[part 2 of 3: packages /E2E to /ComponentTypes]
AUTOSAR XML (schema 00048)
package /E2E
  end to end protection set E2E_ProtectionSet
    end to end protection E2E_Protection_BJB_10_XIX_BMC_CAN01: end-to-end-protection-variable-prototype=receiver=RP_IF_SG_BJB_10_XIX_BMC_HV.DE_SG_BJB_10
    end to end protection E2E_Protection_BMC_HV_10_XIX_BMC_CAN01: end-to-end-protection-variable-prototype=RT_Vishnu.Geltungsbereich_E3_1_2_Premium.SG_BMC_HV_10
    end to end protection E2E_Protection_UI1_01_XIX_BMC_CAN01: end-to-end-protection-variable-prototype=receiver=RP_IF_SG_UI1_01_XIX_BMC_HV.DE_SG_UI1_01
package /ComponentTypes
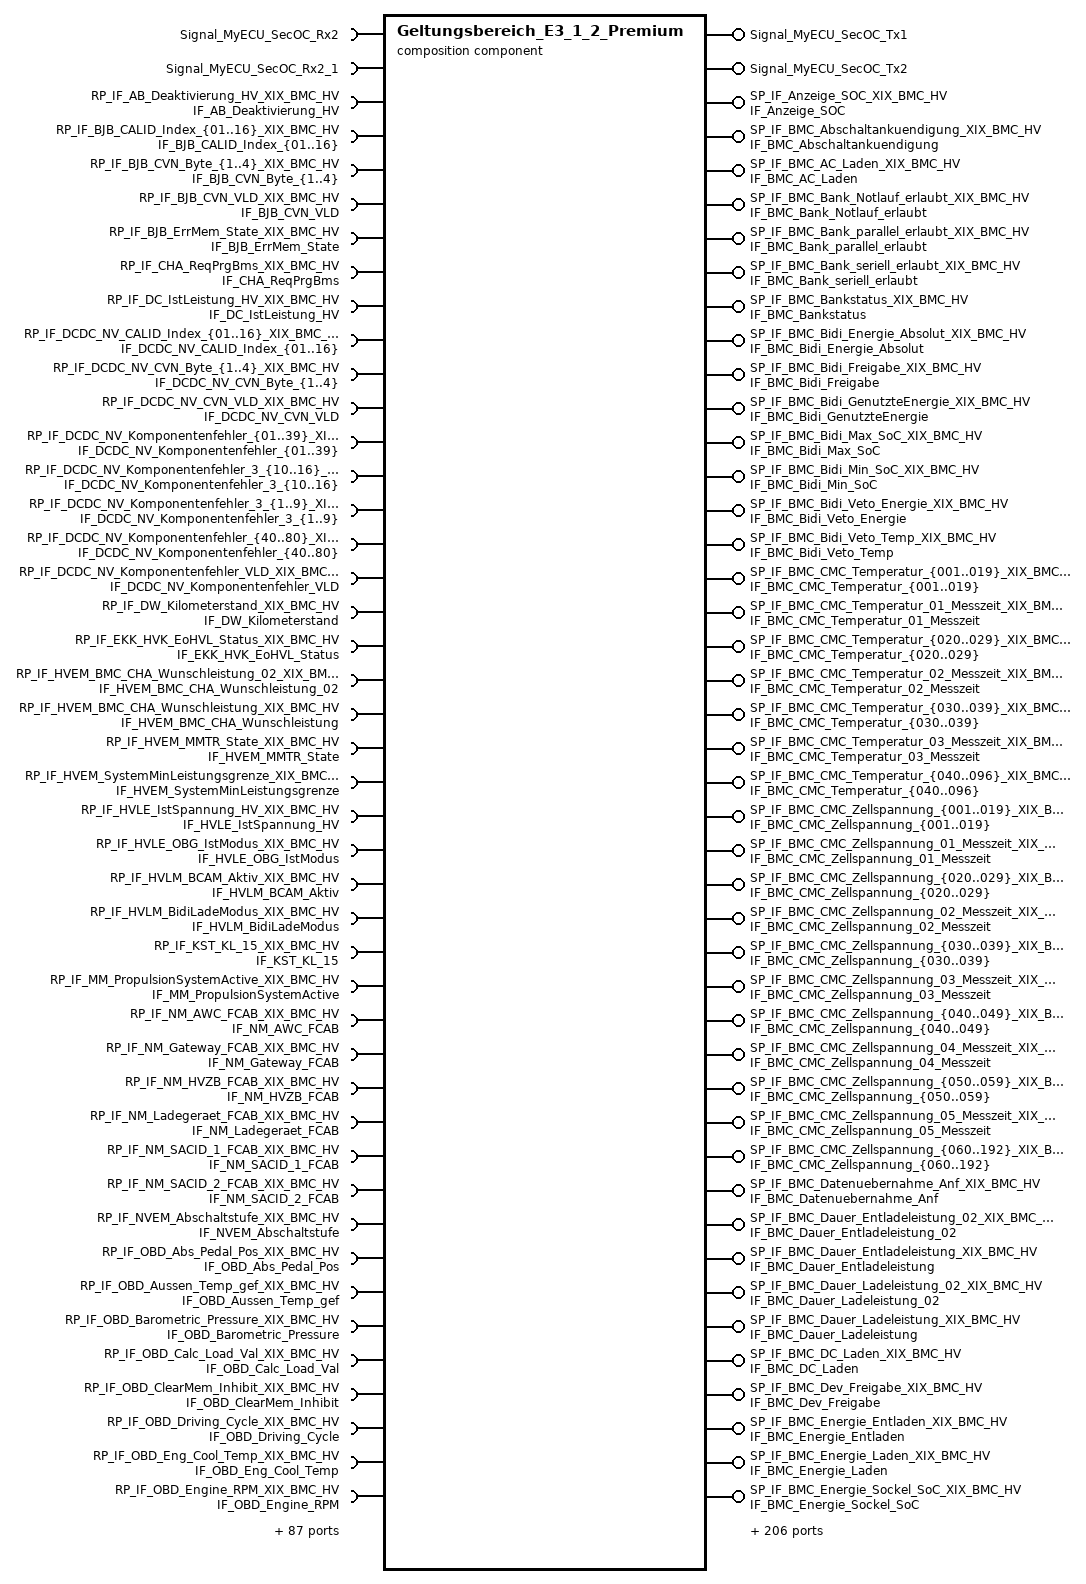
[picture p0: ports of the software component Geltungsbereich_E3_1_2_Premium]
  composition sw component type Geltungsbereich_E3_1_2_Premium
    provide port Signal_MyECU_SecOC_Tx1: nonqueued-sender-com-spec{data-element=Signal_MyECU_SecOC_Tx1, init-value=0}, provided-interface=Signal_MyECU_SecOC_Tx1
    provide port Signal_MyECU_SecOC_Tx2: nonqueued-sender-com-spec{data-element=Signal_MyECU_SecOC_Tx2, init-value=0}, provided-interface=Signal_MyECU_SecOC_Tx2
    require port Signal_MyECU_SecOC_Rx2: nonqueued-receiver-com-spec{data-element=Signal_MyECU_SecOC_Rx2, init-value=0}, required-interface=Signal_MyECU_SecOC_Rx2
    require port Signal_MyECU_SecOC_Rx2_1: nonqueued-receiver-com-spec{data-element=Signal_MyECU_SecOC_Rx2, init-value=0}, required-interface=Signal_MyECU_SecOC_Rx2_1
    519 x provide port:
      SP_IF_Anzeige_SOC_XIX_BMC_HV: nonqueued-sender-com-spec=DE_Anzeige_SOC, provided-interface=IF_Anzeige_SOC
      SP_IF_BMC_Abschaltankuendigung_XIX_BMC_HV: nonqueued-sender-com-spec=DE_BMC_Abschaltankuendigung, provided-interface=IF_BMC_Abschaltankuendigung
      SP_IF_BMC_AC_Laden_XIX_BMC_HV: nonqueued-sender-com-spec=DE_BMC_AC_Laden, provided-interface=IF_BMC_AC_Laden
      SP_IF_BMC_Bank_Notlauf_erlaubt_XIX_BMC_HV: nonqueued-sender-com-spec=DE_BMC_Bank_Notlauf_erlaubt, provided-interface=IF_BMC_Bank_Notlauf_erlaubt
      SP_IF_BMC_Bank_parallel_erlaubt_XIX_BMC_HV: nonqueued-sender-com-spec=DE_BMC_Bank_parallel_erlaubt, provided-interface=IF_BMC_Bank_parallel_erlaubt
      SP_IF_BMC_Bank_seriell_erlaubt_XIX_BMC_HV: nonqueued-sender-com-spec=DE_BMC_Bank_seriell_erlaubt, provided-interface=IF_BMC_Bank_seriell_erlaubt
      SP_IF_BMC_Bankstatus_XIX_BMC_HV: nonqueued-sender-com-spec=DE_BMC_Bankstatus, provided-interface=IF_BMC_Bankstatus
      SP_IF_BMC_Bidi_Energie_Absolut_XIX_BMC_HV: nonqueued-sender-com-spec=DE_BMC_Bidi_Energie_Absolut, provided-interface=IF_BMC_Bidi_Energie_Absolut
      SP_IF_BMC_Bidi_Freigabe_XIX_BMC_HV: nonqueued-sender-com-spec=DE_BMC_Bidi_Freigabe, provided-interface=IF_BMC_Bidi_Freigabe
      SP_IF_BMC_Bidi_GenutzteEnergie_XIX_BMC_HV: nonqueued-sender-com-spec=DE_BMC_Bidi_GenutzteEnergie, provided-interface=IF_BMC_Bidi_GenutzteEnergie
      SP_IF_BMC_Bidi_Max_SoC_XIX_BMC_HV: nonqueued-sender-com-spec=DE_BMC_Bidi_Max_SoC, provided-interface=IF_BMC_Bidi_Max_SoC
      SP_IF_BMC_Bidi_Min_SoC_XIX_BMC_HV: nonqueued-sender-com-spec=DE_BMC_Bidi_Min_SoC, provided-interface=IF_BMC_Bidi_Min_SoC
      SP_IF_BMC_Bidi_Veto_Energie_XIX_BMC_HV: nonqueued-sender-com-spec=DE_BMC_Bidi_Veto_Energie, provided-interface=IF_BMC_Bidi_Veto_Energie
      SP_IF_BMC_Bidi_Veto_Temp_XIX_BMC_HV: nonqueued-sender-com-spec=DE_BMC_Bidi_Veto_Temp, provided-interface=IF_BMC_Bidi_Veto_Temp
      SP_IF_BMC_CMC_Temperatur_{001..019}_XIX_BMC_HV: nonqueued-sender-com-spec=DE_BMC_CMC_Temperatur_{001..019}, provided-interface=IF_BMC_CMC_Temperatur_{001..019}
      SP_IF_BMC_CMC_Temperatur_01_Messzeit_XIX_BMC_HV: nonqueued-sender-com-spec=DE_BMC_CMC_Temperatur_01_Messzeit, provided-interface=IF_BMC_CMC_Temperatur_01_Messzeit
      SP_IF_BMC_CMC_Temperatur_{020..029}_XIX_BMC_HV: nonqueued-sender-com-spec=DE_BMC_CMC_Temperatur_{020..029}, provided-interface=IF_BMC_CMC_Temperatur_{020..029}
      SP_IF_BMC_CMC_Temperatur_02_Messzeit_XIX_BMC_HV: nonqueued-sender-com-spec=DE_BMC_CMC_Temperatur_02_Messzeit, provided-interface=IF_BMC_CMC_Temperatur_02_Messzeit
      SP_IF_BMC_CMC_Temperatur_{030..039}_XIX_BMC_HV: nonqueued-sender-com-spec=DE_BMC_CMC_Temperatur_{030..039}, provided-interface=IF_BMC_CMC_Temperatur_{030..039}
      SP_IF_BMC_CMC_Temperatur_03_Messzeit_XIX_BMC_HV: nonqueued-sender-com-spec=DE_BMC_CMC_Temperatur_03_Messzeit, provided-interface=IF_BMC_CMC_Temperatur_03_Messzeit
      SP_IF_BMC_CMC_Temperatur_{040..096}_XIX_BMC_HV: nonqueued-sender-com-spec=DE_BMC_CMC_Temperatur_{040..096}, provided-interface=IF_BMC_CMC_Temperatur_{040..096}
      SP_IF_BMC_CMC_Zellspannung_{001..019}_XIX_BMC_HV: nonqueued-sender-com-spec=DE_BMC_CMC_Zellspannung_{001..019}, provided-interface=IF_BMC_CMC_Zellspannung_{001..019}
      SP_IF_BMC_CMC_Zellspannung_01_Messzeit_XIX_BMC_HV: nonqueued-sender-com-spec=DE_BMC_CMC_Zellspannung_01_Messzeit, provided-interface=IF_BMC_CMC_Zellspannung_01_Messzeit
      SP_IF_BMC_CMC_Zellspannung_{020..029}_XIX_BMC_HV: nonqueued-sender-com-spec=DE_BMC_CMC_Zellspannung_{020..029}, provided-interface=IF_BMC_CMC_Zellspannung_{020..029}
      SP_IF_BMC_CMC_Zellspannung_02_Messzeit_XIX_BMC_HV: nonqueued-sender-com-spec=DE_BMC_CMC_Zellspannung_02_Messzeit, provided-interface=IF_BMC_CMC_Zellspannung_02_Messzeit
      SP_IF_BMC_CMC_Zellspannung_{030..039}_XIX_BMC_HV: nonqueued-sender-com-spec=DE_BMC_CMC_Zellspannung_{030..039}, provided-interface=IF_BMC_CMC_Zellspannung_{030..039}
      SP_IF_BMC_CMC_Zellspannung_03_Messzeit_XIX_BMC_HV: nonqueued-sender-com-spec=DE_BMC_CMC_Zellspannung_03_Messzeit, provided-interface=IF_BMC_CMC_Zellspannung_03_Messzeit
      SP_IF_BMC_CMC_Zellspannung_{040..049}_XIX_BMC_HV: nonqueued-sender-com-spec=DE_BMC_CMC_Zellspannung_{040..049}, provided-interface=IF_BMC_CMC_Zellspannung_{040..049}
      SP_IF_BMC_CMC_Zellspannung_04_Messzeit_XIX_BMC_HV: nonqueued-sender-com-spec=DE_BMC_CMC_Zellspannung_04_Messzeit, provided-interface=IF_BMC_CMC_Zellspannung_04_Messzeit
      SP_IF_BMC_CMC_Zellspannung_{050..059}_XIX_BMC_HV: nonqueued-sender-com-spec=DE_BMC_CMC_Zellspannung_{050..059}, provided-interface=IF_BMC_CMC_Zellspannung_{050..059}
      SP_IF_BMC_CMC_Zellspannung_05_Messzeit_XIX_BMC_HV: nonqueued-sender-com-spec=DE_BMC_CMC_Zellspannung_05_Messzeit, provided-interface=IF_BMC_CMC_Zellspannung_05_Messzeit
      SP_IF_BMC_CMC_Zellspannung_{060..192}_XIX_BMC_HV: nonqueued-sender-com-spec=DE_BMC_CMC_Zellspannung_{060..192}, provided-interface=IF_BMC_CMC_Zellspannung_{060..192}
      SP_IF_BMC_Datenuebernahme_Anf_XIX_BMC_HV: nonqueued-sender-com-spec=DE_BMC_Datenuebernahme_Anf, provided-interface=IF_BMC_Datenuebernahme_Anf
      SP_IF_BMC_Dauer_Entladeleistung_02_XIX_BMC_HV: nonqueued-sender-com-spec=DE_BMC_Dauer_Entladeleistung_02, provided-interface=IF_BMC_Dauer_Entladeleistung_02
      SP_IF_BMC_Dauer_Entladeleistung_XIX_BMC_HV: nonqueued-sender-com-spec=DE_BMC_Dauer_Entladeleistung, provided-interface=IF_BMC_Dauer_Entladeleistung
      SP_IF_BMC_Dauer_Ladeleistung_02_XIX_BMC_HV: nonqueued-sender-com-spec=DE_BMC_Dauer_Ladeleistung_02, provided-interface=IF_BMC_Dauer_Ladeleistung_02
      SP_IF_BMC_Dauer_Ladeleistung_XIX_BMC_HV: nonqueued-sender-com-spec=DE_BMC_Dauer_Ladeleistung, provided-interface=IF_BMC_Dauer_Ladeleistung
      SP_IF_BMC_DC_Laden_XIX_BMC_HV: nonqueued-sender-com-spec=DE_BMC_DC_Laden, provided-interface=IF_BMC_DC_Laden
      SP_IF_BMC_Dev_Freigabe_XIX_BMC_HV: nonqueued-sender-com-spec=DE_BMC_Dev_Freigabe, provided-interface=IF_BMC_Dev_Freigabe
      SP_IF_BMC_Energie_Entladen_XIX_BMC_HV: nonqueued-sender-com-spec=DE_BMC_Energie_Entladen, provided-interface=IF_BMC_Energie_Entladen
      SP_IF_BMC_Energie_Laden_XIX_BMC_HV: nonqueued-sender-com-spec=DE_BMC_Energie_Laden, provided-interface=IF_BMC_Energie_Laden
      SP_IF_BMC_Energie_Sockel_SoC_XIX_BMC_HV: nonqueued-sender-com-spec=DE_BMC_Energie_Sockel_SoC, provided-interface=IF_BMC_Energie_Sockel_SoC
      SP_IF_BMC_Energieinhalt_XIX_BMC_HV: nonqueued-sender-com-spec=DE_BMC_Energieinhalt, provided-interface=IF_BMC_Energieinhalt
      SP_IF_BMC_EnergieVorhalt_XIX_BMC_HV: nonqueued-sender-com-spec=DE_BMC_EnergieVorhalt, provided-interface=IF_BMC_EnergieVorhalt
      SP_IF_BMC_ExtLadeleistung_XIX_BMC_HV: nonqueued-sender-com-spec=DE_BMC_ExtLadeleistung, provided-interface=IF_BMC_ExtLadeleistung
      SP_IF_BMC_Fehler_Leistungsred_XIX_BMC_HV: nonqueued-sender-com-spec=DE_BMC_Fehler_Leistungsred, provided-interface=IF_BMC_Fehler_Leistungsred
      SP_IF_BMC_Fehler_Warnung_XIX_BMC_HV: nonqueued-sender-com-spec=DE_BMC_Fehler_Warnung, provided-interface=IF_BMC_Fehler_Warnung
      SP_IF_BMC_Flash_Freigabe_XIX_BMC_HV: nonqueued-sender-com-spec=DE_BMC_Flash_Freigabe, provided-interface=IF_BMC_Flash_Freigabe
      SP_IF_BMC_HV_01_BZ_XIX_BMC_HV: nonqueued-sender-com-spec=DE_BMC_HV_01_BZ, provided-interface=IF_BMC_HV_01_BZ
      SP_IF_BMC_HV_01_CRC_XIX_BMC_HV: nonqueued-sender-com-spec=DE_BMC_HV_01_CRC, provided-interface=IF_BMC_HV_01_CRC
      SP_IF_BMC_HV_02_BZ_XIX_BMC_HV: nonqueued-sender-com-spec=DE_BMC_HV_02_BZ, provided-interface=IF_BMC_HV_02_BZ
      SP_IF_BMC_HV_02_CRC_XIX_BMC_HV: nonqueued-sender-com-spec=DE_BMC_HV_02_CRC, provided-interface=IF_BMC_HV_02_CRC
      SP_IF_BMC_HV_04_BZ_XIX_BMC_HV: nonqueued-sender-com-spec=DE_BMC_HV_04_BZ, provided-interface=IF_BMC_HV_04_BZ
      SP_IF_BMC_HV_04_CRC_XIX_BMC_HV: nonqueued-sender-com-spec=DE_BMC_HV_04_CRC, provided-interface=IF_BMC_HV_04_CRC
      SP_IF_BMC_HV_10_BZ_XIX_BMC_HV: nonqueued-sender-com-spec=DE_BMC_HV_10_BZ, provided-interface=IF_BMC_HV_10_BZ
      SP_IF_BMC_HV_10_CRC_XIX_BMC_HV: nonqueued-sender-com-spec=DE_BMC_HV_10_CRC, provided-interface=IF_BMC_HV_10_CRC
      SP_IF_BMC_HV_11_BZ_XIX_BMC_HV: nonqueued-sender-com-spec=DE_BMC_HV_11_BZ, provided-interface=IF_BMC_HV_11_BZ
      SP_IF_BMC_HV_11_CRC_XIX_BMC_HV: nonqueued-sender-com-spec=DE_BMC_HV_11_CRC, provided-interface=IF_BMC_HV_11_CRC
      SP_IF_BMC_HV_12_BZ_XIX_BMC_HV: nonqueued-sender-com-spec=DE_BMC_HV_12_BZ, provided-interface=IF_BMC_HV_12_BZ
      SP_IF_BMC_HV_12_CRC_XIX_BMC_HV: nonqueued-sender-com-spec=DE_BMC_HV_12_CRC, provided-interface=IF_BMC_HV_12_CRC
      SP_IF_BMC_HV_13_BZ_XIX_BMC_HV: nonqueued-sender-com-spec=DE_BMC_HV_13_BZ, provided-interface=IF_BMC_HV_13_BZ
      SP_IF_BMC_HV_13_CRC_XIX_BMC_HV: nonqueued-sender-com-spec=DE_BMC_HV_13_CRC, provided-interface=IF_BMC_HV_13_CRC
      SP_IF_BMC_HVK_EoHVL_Status_XIX_BMC_HV: nonqueued-sender-com-spec=DE_BMC_HVK_EoHVL_Status, provided-interface=IF_BMC_HVK_EoHVL_Status
      SP_IF_BMC_HVK_Fehler_HVIL_XIX_BMC_HV: nonqueued-sender-com-spec=DE_BMC_HVK_Fehler_HVIL, provided-interface=IF_BMC_HVK_Fehler_HVIL
      SP_IF_BMC_HVK_Fehler_Intern_XIX_BMC_HV: nonqueued-sender-com-spec=DE_BMC_HVK_Fehler_Intern, provided-interface=IF_BMC_HVK_Fehler_Intern
      SP_IF_BMC_HVK_Fehler_SD_XIX_BMC_HV: nonqueued-sender-com-spec=DE_BMC_HVK_Fehler_SD, provided-interface=IF_BMC_HVK_Fehler_SD
      SP_IF_BMC_Iso_Mode_Anf_XIX_BMC_HV: nonqueued-sender-com-spec=DE_BMC_Iso_Mode_Anf, provided-interface=IF_BMC_Iso_Mode_Anf
      SP_IF_BMC_IstTemperaturMax_Modul_ID_XIX_BMC_HV: nonqueued-sender-com-spec=DE_BMC_IstTemperaturMax_Modul_ID, provided-interface=IF_BMC_IstTemperaturMax_Modul_ID
      SP_IF_BMC_IstTemperaturMax_Sensor_ID_XIX_BMC_HV: nonqueued-sender-com-spec=DE_BMC_IstTemperaturMax_Sensor_ID, provided-interface=IF_BMC_IstTemperaturMax_Sensor_ID
      SP_IF_BMC_IstTemperaturMin_Modul_ID_XIX_BMC_HV: nonqueued-sender-com-spec=DE_BMC_IstTemperaturMin_Modul_ID, provided-interface=IF_BMC_IstTemperaturMin_Modul_ID
      SP_IF_BMC_IstTemperaturMin_Sensor_ID_XIX_BMC_HV: nonqueued-sender-com-spec=DE_BMC_IstTemperaturMin_Sensor_ID, provided-interface=IF_BMC_IstTemperaturMin_Sensor_ID
      SP_IF_BMC_IstZellSpannungMax_Modul_ID_XIX_BMC_HV: nonqueued-sender-com-spec=DE_BMC_IstZellSpannungMax_Modul_ID, provided-interface=IF_BMC_IstZellSpannungMax_Modul_ID
      SP_IF_BMC_IstZellspannungMax_XIX_BMC_HV: nonqueued-sender-com-spec=DE_BMC_IstZellspannungMax, provided-interface=IF_BMC_IstZellspannungMax
      SP_IF_BMC_IstZellSpannungMax_Zell_ID_XIX_BMC_HV: nonqueued-sender-com-spec=DE_BMC_IstZellSpannungMax_Zell_ID, provided-interface=IF_BMC_IstZellSpannungMax_Zell_ID
      SP_IF_BMC_IstZellSpannungMin_Modul_ID_XIX_BMC_HV: nonqueued-sender-com-spec=DE_BMC_IstZellSpannungMin_Modul_ID, provided-interface=IF_BMC_IstZellSpannungMin_Modul_ID
      SP_IF_BMC_IstZellspannungMin_XIX_BMC_HV: nonqueued-sender-com-spec=DE_BMC_IstZellspannungMin, provided-interface=IF_BMC_IstZellspannungMin
      SP_IF_BMC_IstZellSpannungMin_Zell_ID_XIX_BMC_HV: nonqueued-sender-com-spec=DE_BMC_IstZellSpannungMin_Zell_ID, provided-interface=IF_BMC_IstZellSpannungMin_Zell_ID
      SP_IF_BMC_IWU_Status_XIX_BMC_HV: nonqueued-sender-com-spec=DE_BMC_IWU_Status, provided-interface=IF_BMC_IWU_Status
      SP_IF_BMC_IWU_Wert_neg_XIX_BMC_HV: nonqueued-sender-com-spec=DE_BMC_IWU_Wert_neg, provided-interface=IF_BMC_IWU_Wert_neg
      SP_IF_BMC_IWU_Wert_pos_XIX_BMC_HV: nonqueued-sender-com-spec=DE_BMC_IWU_Wert_pos, provided-interface=IF_BMC_IWU_Wert_pos
      SP_IF_BMC_Konditionierung_Anf_XIX_BMC_HV: nonqueued-sender-com-spec=DE_BMC_Konditionierung_Anf, provided-interface=IF_BMC_Konditionierung_Anf
      SP_IF_BMC_KundenWarnung_XIX_BMC_HV: nonqueued-sender-com-spec=DE_BMC_KundenWarnung, provided-interface=IF_BMC_KundenWarnung
      SP_IF_BMC_Lebensdauer_Trennelemente_XIX_BMC_HV: nonqueued-sender-com-spec=DE_BMC_Lebensdauer_Trennelemente, provided-interface=IF_BMC_Lebensdauer_Trennelemente
      SP_IF_BMC_Leerlaufspannung_XIX_BMC_HV: nonqueued-sender-com-spec=DE_BMC_Leerlaufspannung, provided-interface=IF_BMC_Leerlaufspannung
      SP_IF_BMC_Max_Entladeleistung_02_XIX_BMC_HV: nonqueued-sender-com-spec=DE_BMC_Max_Entladeleistung_02, provided-interface=IF_BMC_Max_Entladeleistung_02
      SP_IF_BMC_Max_Entladeleistung_XIX_BMC_HV: nonqueued-sender-com-spec=DE_BMC_Max_Entladeleistung, provided-interface=IF_BMC_Max_Entladeleistung
      SP_IF_BMC_Max_Entladestrom_02_XIX_BMC_HV: nonqueued-sender-com-spec=DE_BMC_Max_Entladestrom_02, provided-interface=IF_BMC_Max_Entladestrom_02
      SP_IF_BMC_Max_Entladestrom_XIX_BMC_HV: nonqueued-sender-com-spec=DE_BMC_Max_Entladestrom, provided-interface=IF_BMC_Max_Entladestrom
      SP_IF_BMC_Max_Ladeleistung_02_XIX_BMC_HV: nonqueued-sender-com-spec=DE_BMC_Max_Ladeleistung_02, provided-interface=IF_BMC_Max_Ladeleistung_02
      SP_IF_BMC_Max_Ladeleistung_XIX_BMC_HV: nonqueued-sender-com-spec=DE_BMC_Max_Ladeleistung, provided-interface=IF_BMC_Max_Ladeleistung
      SP_IF_BMC_Max_Ladestrom_02_XIX_BMC_HV: nonqueued-sender-com-spec=DE_BMC_Max_Ladestrom_02, provided-interface=IF_BMC_Max_Ladestrom_02
      SP_IF_BMC_Max_Ladestrom_XIX_BMC_HV: nonqueued-sender-com-spec=DE_BMC_Max_Ladestrom, provided-interface=IF_BMC_Max_Ladestrom
      SP_IF_BMC_Max_Spannung_XIX_BMC_HV: nonqueued-sender-com-spec=DE_BMC_Max_Spannung, provided-interface=IF_BMC_Max_Spannung
      SP_IF_BMC_MaxEnergieinhalt_XIX_BMC_HV: nonqueued-sender-com-spec=DE_BMC_MaxEnergieinhalt, provided-interface=IF_BMC_MaxEnergieinhalt
      SP_IF_BMC_Min_Spannung_XIX_BMC_HV: nonqueued-sender-com-spec=DE_BMC_Min_Spannung, provided-interface=IF_BMC_Min_Spannung
      SP_IF_BMC_MinDyn_Entladespannung_XIX_BMC_HV: nonqueued-sender-com-spec=DE_BMC_MinDyn_Entladespannung, provided-interface=IF_BMC_MinDyn_Entladespannung
      SP_IF_BMC_MinDyn_Ladespannung_XIX_BMC_HV: nonqueued-sender-com-spec=DE_BMC_MinDyn_Ladespannung, provided-interface=IF_BMC_MinDyn_Ladespannung
      SP_IF_BMC_MMTR_Status_XIX_BMC_HV: nonqueued-sender-com-spec=DE_BMC_MMTR_Status, provided-interface=IF_BMC_MMTR_Status
      SP_IF_BMC_Modus_XIX_BMC_HV: nonqueued-sender-com-spec=DE_BMC_Modus, provided-interface=IF_BMC_Modus
      SP_IF_BMC_NutzbareKapazitaet_XIX_BMC_HV: nonqueued-sender-com-spec=DE_BMC_NutzbareKapazitaet, provided-interface=IF_BMC_NutzbareKapazitaet
      SP_IF_BMC_NutzbarerSOC_XIX_BMC_HV: nonqueued-sender-com-spec=DE_BMC_NutzbarerSOC, provided-interface=IF_BMC_NutzbarerSOC
      SP_IF_BMC_Pack_SN_{01..26}_XIX_BMC_HV: nonqueued-sender-com-spec=DE_BMC_Pack_SN_{01..26}, provided-interface=IF_BMC_Pack_SN_{01..26}
      SP_IF_BMC_PCM_VTD_Freeze_Req_XIX_BMC_HV: nonqueued-sender-com-spec=DE_BMC_PCM_VTD_Freeze_Req, provided-interface=IF_BMC_PCM_VTD_Freeze_Req
      SP_IF_BMC_PCM_VTD_LifeTimeReset_Req_XIX_BMC_HV: nonqueued-sender-com-spec=DE_BMC_PCM_VTD_LifeTimeReset_Req, provided-interface=IF_BMC_PCM_VTD_LifeTimeReset_Req
      SP_IF_BMC_PCM_VTD_LifeTimeReset_Resp_XIX_BMC_HV: nonqueued-sender-com-spec=DE_BMC_PCM_VTD_LifeTimeReset_Resp, provided-interface=IF_BMC_PCM_VTD_LifeTimeReset_Resp
      SP_IF_BMC_PCM_VTD_RecentReset_Req_XIX_BMC_HV: nonqueued-sender-com-spec=DE_BMC_PCM_VTD_RecentReset_Req, provided-interface=IF_BMC_PCM_VTD_RecentReset_Req
      SP_IF_BMC_PerfInd_Entladen_XIX_BMC_HV: nonqueued-sender-com-spec=DE_BMC_PerfInd_Entladen, provided-interface=IF_BMC_PerfInd_Entladen
      SP_IF_BMC_PerfInd_Laden_XIX_BMC_HV: nonqueued-sender-com-spec=DE_BMC_PerfInd_Laden, provided-interface=IF_BMC_PerfInd_Laden
      SP_IF_BMC_PredLeistung_StuetzungNV_XIX_BMC_HV: nonqueued-sender-com-spec=DE_BMC_PredLeistung_StuetzungNV, provided-interface=IF_BMC_PredLeistung_StuetzungNV
      SP_IF_BMC_Range_Indikator_XIX_BMC_HV: nonqueued-sender-com-spec=DE_BMC_Range_Indikator, provided-interface=IF_BMC_Range_Indikator
      SP_IF_BMC_Rekuperation_Ueberlauf_XIX_BMC_HV: nonqueued-sender-com-spec=DE_BMC_Rekuperation_Ueberlauf, provided-interface=IF_BMC_Rekuperation_Ueberlauf
      SP_IF_BMC_Rekuperation_XIX_BMC_HV: nonqueued-sender-com-spec=DE_BMC_Rekuperation, provided-interface=IF_BMC_Rekuperation
      SP_IF_BMC_RtmWarnBattUnautorisiert_XIX_BMC_HV: nonqueued-sender-com-spec=DE_BMC_RtmWarnBattUnautorisiert, provided-interface=IF_BMC_RtmWarnBattUnautorisiert
      SP_IF_BMC_RtmWarnPackKommunikation_XIX_BMC_HV: nonqueued-sender-com-spec=DE_BMC_RtmWarnPackKommunikation, provided-interface=IF_BMC_RtmWarnPackKommunikation
      SP_IF_BMC_RtmWarnPackUeberladen_XIX_BMC_HV: nonqueued-sender-com-spec=DE_BMC_RtmWarnPackUeberladen, provided-interface=IF_BMC_RtmWarnPackUeberladen
      SP_IF_BMC_RtmWarnSocHoch_XIX_BMC_HV: nonqueued-sender-com-spec=DE_BMC_RtmWarnSocHoch, provided-interface=IF_BMC_RtmWarnSocHoch
      SP_IF_BMC_RtmWarnSocNiedrig_XIX_BMC_HV: nonqueued-sender-com-spec=DE_BMC_RtmWarnSocNiedrig, provided-interface=IF_BMC_RtmWarnSocNiedrig
      SP_IF_BMC_RtmWarnSocSprung_XIX_BMC_HV: nonqueued-sender-com-spec=DE_BMC_RtmWarnSocSprung, provided-interface=IF_BMC_RtmWarnSocSprung
      SP_IF_BMC_RtmWarnTZelleDiff_XIX_BMC_HV: nonqueued-sender-com-spec=DE_BMC_RtmWarnTZelleDiff, provided-interface=IF_BMC_RtmWarnTZelleDiff
      SP_IF_BMC_RtmWarnTZelleMax_XIX_BMC_HV: nonqueued-sender-com-spec=DE_BMC_RtmWarnTZelleMax, provided-interface=IF_BMC_RtmWarnTZelleMax
      SP_IF_BMC_RtmWarnTZelleMin_XIX_BMC_HV: nonqueued-sender-com-spec=DE_BMC_RtmWarnTZelleMin, provided-interface=IF_BMC_RtmWarnTZelleMin
      SP_IF_BMC_RtmWarnUeberstrom_XIX_BMC_HV: nonqueued-sender-com-spec=DE_BMC_RtmWarnUeberstrom, provided-interface=IF_BMC_RtmWarnUeberstrom
      SP_IF_BMC_RtmWarnUPackMax_XIX_BMC_HV: nonqueued-sender-com-spec=DE_BMC_RtmWarnUPackMax, provided-interface=IF_BMC_RtmWarnUPackMax
      SP_IF_BMC_RtmWarnUPackMin_XIX_BMC_HV: nonqueued-sender-com-spec=DE_BMC_RtmWarnUPackMin, provided-interface=IF_BMC_RtmWarnUPackMin
      SP_IF_BMC_RtmWarnUZelleMax_XIX_BMC_HV: nonqueued-sender-com-spec=DE_BMC_RtmWarnUZelleMax, provided-interface=IF_BMC_RtmWarnUZelleMax
      SP_IF_BMC_RtmWarnUZelleMin_XIX_BMC_HV: nonqueued-sender-com-spec=DE_BMC_RtmWarnUZelleMin, provided-interface=IF_BMC_RtmWarnUZelleMin
      SP_IF_BMC_RtmWarnZelleZustand_XIX_BMC_HV: nonqueued-sender-com-spec=DE_BMC_RtmWarnZelleZustand, provided-interface=IF_BMC_RtmWarnZelleZustand
      SP_IF_BMC_RuecklaufTemperatur_XIX_BMC_HV: nonqueued-sender-com-spec=DE_BMC_RuecklaufTemperatur, provided-interface=IF_BMC_RuecklaufTemperatur
      SP_IF_BMC_Spannung_DC_Ladesaeule_XIX_BMC_HV: nonqueued-sender-com-spec=DE_BMC_Spannung_DC_Ladesaeule, provided-interface=IF_BMC_Spannung_DC_Ladesaeule
      SP_IF_BMC_Spannung_Messzeit_XIX_BMC_HV: nonqueued-sender-com-spec=DE_BMC_Spannung_Messzeit, provided-interface=IF_BMC_Spannung_Messzeit
      SP_IF_BMC_Spannung_XIX_BMC_HV: nonqueued-sender-com-spec=DE_BMC_Spannung, provided-interface=IF_BMC_Spannung
      SP_IF_BMC_Spannung_ZwischenKreis_2_XIX_BMC_HV: nonqueued-sender-com-spec=DE_BMC_Spannung_ZwischenKreis_2, provided-interface=IF_BMC_Spannung_ZwischenKreis_2
      SP_IF_BMC_Spannung_ZwischenKreis_XIX_BMC_HV: nonqueued-sender-com-spec=DE_BMC_Spannung_ZwischenKreis, provided-interface=IF_BMC_Spannung_ZwischenKreis
      SP_IF_BMC_Sperrung_Ueberspannung_XIX_BMC_HV: nonqueued-sender-com-spec=DE_BMC_Sperrung_Ueberspannung, provided-interface=IF_BMC_Sperrung_Ueberspannung
      SP_IF_BMC_Sperrung_Uebertemperatur_XIX_BMC_HV: nonqueued-sender-com-spec=DE_BMC_Sperrung_Uebertemperatur, provided-interface=IF_BMC_Sperrung_Uebertemperatur
      SP_IF_BMC_Sperrung_Unterspannung_XIX_BMC_HV: nonqueued-sender-com-spec=DE_BMC_Sperrung_Unterspannung, provided-interface=IF_BMC_Sperrung_Unterspannung
      SP_IF_BMC_Status_DCLS_XIX_BMC_HV: nonqueued-sender-com-spec=DE_BMC_Status_DCLS, provided-interface=IF_BMC_Status_DCLS
      SP_IF_BMC_Status_HV_Spannungssensorik_XIX_BMC_HV: nonqueued-sender-com-spec=DE_BMC_Status_HV_Spannungssensorik, provided-interface=IF_BMC_Status_HV_Spannungssensorik
      SP_IF_BMC_Status_Spgfreiheit_XIX_BMC_HV: nonqueued-sender-com-spec=DE_BMC_Status_Spgfreiheit, provided-interface=IF_BMC_Status_Spgfreiheit
      SP_IF_BMC_Status_Trennelemente_XIX_BMC_HV: nonqueued-sender-com-spec=DE_BMC_Status_Trennelemente, provided-interface=IF_BMC_Status_Trennelemente
      SP_IF_BMC_Strom_02_XIX_BMC_HV: nonqueued-sender-com-spec=DE_BMC_Strom_02, provided-interface=IF_BMC_Strom_02
      SP_IF_BMC_Strom_Messzeit_XIX_BMC_HV: nonqueued-sender-com-spec=DE_BMC_Strom_Messzeit, provided-interface=IF_BMC_Strom_Messzeit
      SP_IF_BMC_Strom_XIX_BMC_HV: nonqueued-sender-com-spec=DE_BMC_Strom, provided-interface=IF_BMC_Strom
      SP_IF_BMC_TechnischerSOC_XIX_BMC_HV: nonqueued-sender-com-spec=DE_BMC_TechnischerSOC, provided-interface=IF_BMC_TechnischerSOC
      SP_IF_BMC_Temperatur_hoechste_XIX_BMC_HV: nonqueued-sender-com-spec=DE_BMC_Temperatur_hoechste, provided-interface=IF_BMC_Temperatur_hoechste
      SP_IF_BMC_Temperatur_niedrigste_XIX_BMC_HV: nonqueued-sender-com-spec=DE_BMC_Temperatur_niedrigste, provided-interface=IF_BMC_Temperatur_niedrigste
      SP_IF_BMC_Temperatur_XIX_BMC_HV: nonqueued-sender-com-spec=DE_BMC_Temperatur, provided-interface=IF_BMC_Temperatur
      SP_IF_BMC_ThermAuslastung_XIX_BMC_HV: nonqueued-sender-com-spec=DE_BMC_ThermAuslastung, provided-interface=IF_BMC_ThermAuslastung
      SP_IF_BMC_ThermSpreizung_XIX_BMC_HV: nonqueued-sender-com-spec=DE_BMC_ThermSpreizung, provided-interface=IF_BMC_ThermSpreizung
      SP_IF_BMC_UBE_Indik_last_update_km_XIX_BMC_HV: nonqueued-sender-com-spec=DE_BMC_UBE_Indik_last_update_km, provided-interface=IF_BMC_UBE_Indik_last_update_km
      SP_IF_BMC_UBE_Indikator_XIX_BMC_HV: nonqueued-sender-com-spec=DE_BMC_UBE_Indikator, provided-interface=IF_BMC_UBE_Indikator
      SP_IF_BMC_Ueberspannungszaehler_CMC{01..04}_XIX_BMC_HV: nonqueued-sender-com-spec=DE_BMC_Ueberspannungszaehler_CMC{01..04}, provided-interface=IF_BMC_Ueberspannungszaehler_CMC{01..04}
      SP_IF_BMC_Uebertemperaturzaehler_CMC{01..04}_XIX_BMC_HV: nonqueued-sender-com-spec=DE_BMC_Uebertemperaturzaehler_CMC{01..04}, provided-interface=IF_BMC_Uebertemperaturzaehler_CMC{01..04}
      SP_IF_BMC_UI1_Spannung1_Schalt_Anf_XIX_BMC_HV: nonqueued-sender-com-spec=DE_BMC_UI1_Spannung1_Schalt_Anf, provided-interface=IF_BMC_UI1_Spannung1_Schalt_Anf
      SP_IF_BMC_UI1_Spannung2_Schalt_Anf_XIX_BMC_HV: nonqueued-sender-com-spec=DE_BMC_UI1_Spannung2_Schalt_Anf, provided-interface=IF_BMC_UI1_Spannung2_Schalt_Anf
      SP_IF_BMC_UI2_Spannung1_Schalt_Anf_XIX_BMC_HV: nonqueued-sender-com-spec=DE_BMC_UI2_Spannung1_Schalt_Anf, provided-interface=IF_BMC_UI2_Spannung1_Schalt_Anf
      SP_IF_BMC_UI2_Spannung2_Schalt_Anf_XIX_BMC_HV: nonqueued-sender-com-spec=DE_BMC_UI2_Spannung2_Schalt_Anf, provided-interface=IF_BMC_UI2_Spannung2_Schalt_Anf
      SP_IF_BMC_Unterboden_Warnung_XIX_BMC_HV: nonqueued-sender-com-spec=DE_BMC_Unterboden_Warnung, provided-interface=IF_BMC_Unterboden_Warnung
      SP_IF_BMC_Unterspannungszaehler_CMC{01..04}_XIX_BMC_HV: nonqueued-sender-com-spec=DE_BMC_Unterspannungszaehler_CMC{01..04}, provided-interface=IF_BMC_Unterspannungszaehler_CMC{01..04}
      SP_IF_BMC_Verbauinfo_ACSchuetz_XIX_BMC_HV: nonqueued-sender-com-spec=DE_BMC_Verbauinfo_ACSchuetz, provided-interface=IF_BMC_Verbauinfo_ACSchuetz
      SP_IF_BMC_Verbauinfo_Bank_XIX_BMC_HV: nonqueued-sender-com-spec=DE_BMC_Verbauinfo_Bank, provided-interface=IF_BMC_Verbauinfo_Bank
      SP_IF_BMC_Verbrauch_Ueberlauf_XIX_BMC_HV: nonqueued-sender-com-spec=DE_BMC_Verbrauch_Ueberlauf, provided-interface=IF_BMC_Verbrauch_Ueberlauf
      SP_IF_BMC_Verbrauch_XIX_BMC_HV: nonqueued-sender-com-spec=DE_BMC_Verbrauch, provided-interface=IF_BMC_Verbrauch
      SP_IF_BMC_VerlustEnergie_XIX_BMC_HV: nonqueued-sender-com-spec=DE_BMC_VerlustEnergie, provided-interface=IF_BMC_VerlustEnergie
      SP_IF_BMC_Vorlade_Zielspannung_XIX_BMC_HV: nonqueued-sender-com-spec=DE_BMC_Vorlade_Zielspannung, provided-interface=IF_BMC_Vorlade_Zielspannung
      SP_IF_BMC_VorlaufTemperatur_XIX_BMC_HV: nonqueued-sender-com-spec=DE_BMC_VorlaufTemperatur, provided-interface=IF_BMC_VorlaufTemperatur
      SP_IF_BMC_ZellTemp_virtuell_max_XIX_BMC_HV: nonqueued-sender-com-spec=DE_BMC_ZellTemp_virtuell_max, provided-interface=IF_BMC_ZellTemp_virtuell_max
      SP_IF_BMC_ZellTemp_virtuell_min_XIX_BMC_HV: nonqueued-sender-com-spec=DE_BMC_ZellTemp_virtuell_min, provided-interface=IF_BMC_ZellTemp_virtuell_min
      SP_IF_DS_Hybrid_01_ConfDTCChanged_XIX_BMC_HV: nonqueued-sender-com-spec=DE_DS_Hybrid_01_ConfDTCChanged, provided-interface=IF_DS_Hybrid_01_ConfDTCChanged
      SP_IF_DS_Hybrid_01_DiagAdr_XIX_BMC_HV: nonqueued-sender-com-spec=DE_DS_Hybrid_01_DiagAdr, provided-interface=IF_DS_Hybrid_01_DiagAdr
      SP_IF_DS_Hybrid_01_IdentValid_XIX_BMC_HV: nonqueued-sender-com-spec=DE_DS_Hybrid_01_IdentValid, provided-interface=IF_DS_Hybrid_01_IdentValid
      SP_IF_DS_Hybrid_01_Lokalaktiv_XIX_BMC_HV: nonqueued-sender-com-spec=DE_DS_Hybrid_01_Lokalaktiv, provided-interface=IF_DS_Hybrid_01_Lokalaktiv
      SP_IF_DS_Hybrid_01_MemSel10Changed_XIX_BMC_HV: nonqueued-sender-com-spec=DE_DS_Hybrid_01_MemSel10Changed, provided-interface=IF_DS_Hybrid_01_MemSel10Changed
      SP_IF_DS_Hybrid_01_MemSelChanged_XIX_BMC_HV: nonqueued-sender-com-spec=DE_DS_Hybrid_01_MemSelChanged, provided-interface=IF_DS_Hybrid_01_MemSelChanged
      SP_IF_DS_Hybrid_01_StMemChanged_XIX_BMC_HV: nonqueued-sender-com-spec=DE_DS_Hybrid_01_StMemChanged, provided-interface=IF_DS_Hybrid_01_StMemChanged
      SP_IF_DS_Hybrid_01_Subsystemaktiv_XIX_BMC_HV: nonqueued-sender-com-spec=DE_DS_Hybrid_01_Subsystemaktiv, provided-interface=IF_DS_Hybrid_01_Subsystemaktiv
      SP_IF_DS_Hybrid_01_TestFailedChanged_XIX_BMC_HV: nonqueued-sender-com-spec=DE_DS_Hybrid_01_TestFailedChanged, provided-interface=IF_DS_Hybrid_01_TestFailedChanged
      SP_IF_DS_Hybrid_01_WIRChanged_XIX_BMC_HV: nonqueued-sender-com-spec=DE_DS_Hybrid_01_WIRChanged, provided-interface=IF_DS_Hybrid_01_WIRChanged
      SP_IF_Hybrid_01_Indc_StChk_XIX_BMC_HV: nonqueued-sender-com-spec=DE_Hybrid_01_Indc_StChk, provided-interface=IF_Hybrid_01_Indc_StChk
      SP_IF_Hybrid_01_Indc_StFail_XIX_BMC_HV: nonqueued-sender-com-spec=DE_Hybrid_01_Indc_StFail, provided-interface=IF_Hybrid_01_Indc_StFail
      SP_IF_Hybrid_01_KD_Fehler_XIX_BMC_HV: nonqueued-sender-com-spec=DE_Hybrid_01_KD_Fehler, provided-interface=IF_Hybrid_01_KD_Fehler
      SP_IF_Hybrid_01_Nachlauftyp_XIX_BMC_HV: nonqueued-sender-com-spec=DE_Hybrid_01_Nachlauftyp, provided-interface=IF_Hybrid_01_Nachlauftyp
      SP_IF_Hybrid_01_OBD_Lampe_Anf_XIX_BMC_HV: nonqueued-sender-com-spec=DE_Hybrid_01_OBD_Lampe_Anf, provided-interface=IF_Hybrid_01_OBD_Lampe_Anf
      SP_IF_Hybrid_01_SNI_10_XIX_BMC_HV: nonqueued-sender-com-spec=DE_Hybrid_01_SNI_10, provided-interface=IF_Hybrid_01_SNI_10
      SP_IF_KN_Hybrid_01_DiagPfad_V12_XIX_BMC_HV: nonqueued-sender-com-spec=DE_KN_Hybrid_01_DiagPfad_V12, provided-interface=IF_KN_Hybrid_01_DiagPfad_V12
      SP_IF_KS_Hybrid_01_ChK_IKACtr_XIX_BMC_HV: nonqueued-sender-com-spec=DE_KS_Hybrid_01_ChK_IKACtr, provided-interface=IF_KS_Hybrid_01_ChK_IKACtr
      SP_IF_KS_Hybrid_01_ChK_SID_XIX_BMC_HV: nonqueued-sender-com-spec=DE_KS_Hybrid_01_ChK_SID, provided-interface=IF_KS_Hybrid_01_ChK_SID
      SP_IF_KS_Hybrid_01_ChK_XIX_BMC_HV: nonqueued-sender-com-spec=DE_KS_Hybrid_01_ChK, provided-interface=IF_KS_Hybrid_01_ChK
      SP_IF_KS_Hybrid_01_ReK_IKACtr_XIX_BMC_HV: nonqueued-sender-com-spec=DE_KS_Hybrid_01_ReK_IKACtr, provided-interface=IF_KS_Hybrid_01_ReK_IKACtr
      SP_IF_KS_Hybrid_01_ReK_SID_XIX_BMC_HV: nonqueued-sender-com-spec=DE_KS_Hybrid_01_ReK_SID, provided-interface=IF_KS_Hybrid_01_ReK_SID
      SP_IF_KS_Hybrid_01_ReK_XIX_BMC_HV: nonqueued-sender-com-spec=DE_KS_Hybrid_01_ReK, provided-interface=IF_KS_Hybrid_01_ReK
      SP_IF_KS_Hybrid_01_Req_ErrCtr_XIX_BMC_HV: nonqueued-sender-com-spec=DE_KS_Hybrid_01_Req_ErrCtr, provided-interface=IF_KS_Hybrid_01_Req_ErrCtr
      SP_IF_KS_Hybrid_01_Req_IKA_Retry_XIX_BMC_HV: nonqueued-sender-com-spec=DE_KS_Hybrid_01_Req_IKA_Retry, provided-interface=IF_KS_Hybrid_01_Req_IKA_Retry
      SP_IF_KS_Hybrid_01_Req_Prio_XIX_BMC_HV: nonqueued-sender-com-spec=DE_KS_Hybrid_01_Req_Prio, provided-interface=IF_KS_Hybrid_01_Req_Prio
      SP_IF_KS_Hybrid_01_Req_SID_XIX_BMC_HV: nonqueued-sender-com-spec=DE_KS_Hybrid_01_Req_SID, provided-interface=IF_KS_Hybrid_01_Req_SID
      SP_IF_KS_Hybrid_01_Req_SWMaj_XIX_BMC_HV: nonqueued-sender-com-spec=DE_KS_Hybrid_01_Req_SWMaj, provided-interface=IF_KS_Hybrid_01_Req_SWMaj
      SP_IF_KS_Hybrid_01_Req_SWMin_XIX_BMC_HV: nonqueued-sender-com-spec=DE_KS_Hybrid_01_Req_SWMin, provided-interface=IF_KS_Hybrid_01_Req_SWMin
      SP_IF_KS_Hybrid_01_Req_SWPat_XIX_BMC_HV: nonqueued-sender-com-spec=DE_KS_Hybrid_01_Req_SWPat, provided-interface=IF_KS_Hybrid_01_Req_SWPat
      SP_IF_KS_Hybrid_01_Req_VKMS_Err_XIX_BMC_HV: nonqueued-sender-com-spec=DE_KS_Hybrid_01_Req_VKMS_Err, provided-interface=IF_KS_Hybrid_01_Req_VKMS_Err
      SP_IF_NM_Hybrid_01_CAB_V12_XIX_BMC_HV: nonqueued-sender-com-spec=DE_NM_Hybrid_01_CAB_V12, provided-interface=IF_NM_Hybrid_01_CAB_V12
      SP_IF_NM_Hybrid_01_CBV_AWB_XIX_BMC_HV: nonqueued-sender-com-spec=DE_NM_Hybrid_01_CBV_AWB, provided-interface=IF_NM_Hybrid_01_CBV_AWB
      SP_IF_NM_Hybrid_01_FCAB_XIX_BMC_HV: nonqueued-sender-com-spec=DE_NM_Hybrid_01_FCAB, provided-interface=IF_NM_Hybrid_01_FCAB
      SP_IF_NM_Hybrid_01_FCIB_XIX_BMC_HV: nonqueued-sender-com-spec=DE_NM_Hybrid_01_FCIB, provided-interface=IF_NM_Hybrid_01_FCIB
      SP_IF_NM_Hybrid_01_NM_State_XIX_BMC_HV: nonqueued-sender-com-spec=DE_NM_Hybrid_01_NM_State, provided-interface=IF_NM_Hybrid_01_NM_State
      SP_IF_NM_Hybrid_01_SNI_10_XIX_BMC_HV: nonqueued-sender-com-spec=DE_NM_Hybrid_01_SNI_10, provided-interface=IF_NM_Hybrid_01_SNI_10
      SP_IF_OBDProtocol_Hybrid_01_XIX_BMC_HV: nonqueued-sender-com-spec=DE_OBDProtocol_Hybrid_01, provided-interface=IF_OBDProtocol_Hybrid_01
      SP_IF_SOK_Zeit_Hybrid_01_Challenge_XIX_BMC_HV: nonqueued-sender-com-spec=DE_SOK_Zeit_Hybrid_01_Challenge, provided-interface=IF_SOK_Zeit_Hybrid_01_Challenge
    383 x require port:
      RP_IF_AB_Deaktivierung_HV_XIX_BMC_HV: nonqueued-receiver-com-spec=data-element=DE_AB_Deaktivierung_HV, required-interface=IF_AB_Deaktivierung_HV
      RP_IF_BJB_CALID_Index_{01..16}_XIX_BMC_HV: nonqueued-receiver-com-spec=data-element=DE_BJB_CALID_Index_{01..16}, required-interface=IF_BJB_CALID_Index_{01..16}
      RP_IF_BJB_CVN_Byte_{1..4}_XIX_BMC_HV: nonqueued-receiver-com-spec=data-element=DE_BJB_CVN_Byte_{1..4}, required-interface=IF_BJB_CVN_Byte_{1..4}
      RP_IF_BJB_CVN_VLD_XIX_BMC_HV: nonqueued-receiver-com-spec=data-element=DE_BJB_CVN_VLD, required-interface=IF_BJB_CVN_VLD
      RP_IF_BJB_ErrMem_State_XIX_BMC_HV: nonqueued-receiver-com-spec=data-element=DE_BJB_ErrMem_State, required-interface=IF_BJB_ErrMem_State
      RP_IF_CHA_ReqPrgBms_XIX_BMC_HV: nonqueued-receiver-com-spec=data-element=DE_CHA_ReqPrgBms, required-interface=IF_CHA_ReqPrgBms
      RP_IF_DC_IstLeistung_HV_XIX_BMC_HV: nonqueued-receiver-com-spec=data-element=DE_DC_IstLeistung_HV, required-interface=IF_DC_IstLeistung_HV
      RP_IF_DCDC_NV_CALID_Index_{01..16}_XIX_BMC_HV: nonqueued-receiver-com-spec=data-element=DE_DCDC_NV_CALID_Index_{01..16}, required-interface=IF_DCDC_NV_CALID_Index_{01..16}
      RP_IF_DCDC_NV_CVN_Byte_{1..4}_XIX_BMC_HV: nonqueued-receiver-com-spec=data-element=DE_DCDC_NV_CVN_Byte_{1..4}, required-interface=IF_DCDC_NV_CVN_Byte_{1..4}
      RP_IF_DCDC_NV_CVN_VLD_XIX_BMC_HV: nonqueued-receiver-com-spec=data-element=DE_DCDC_NV_CVN_VLD, required-interface=IF_DCDC_NV_CVN_VLD
      RP_IF_DCDC_NV_Komponentenfehler_{01..39}_XIX_BMC_HV: nonqueued-receiver-com-spec=data-element=DE_DCDC_NV_Komponentenfehler_{01..39}, required-interface=IF_DCDC_NV_Komponentenfehler_{01..39}
      RP_IF_DCDC_NV_Komponentenfehler_3_{10..16}_XIX_BMC_HV: nonqueued-receiver-com-spec=data-element=DE_DCDC_NV_Komponentenfehler_3_{10..16}, required-interface=IF_DCDC_NV_Komponentenfehler_3_{10..16}
      RP_IF_DCDC_NV_Komponentenfehler_3_{1..9}_XIX_BMC_HV: nonqueued-receiver-com-spec=data-element=DE_DCDC_NV_Komponentenfehler_3_{1..9}, required-interface=IF_DCDC_NV_Komponentenfehler_3_{1..9}
      RP_IF_DCDC_NV_Komponentenfehler_{40..80}_XIX_BMC_HV: nonqueued-receiver-com-spec=data-element=DE_DCDC_NV_Komponentenfehler_{40..80}, required-interface=IF_DCDC_NV_Komponentenfehler_{40..80}
      RP_IF_DCDC_NV_Komponentenfehler_VLD_XIX_BMC_HV: nonqueued-receiver-com-spec=data-element=DE_DCDC_NV_Komponentenfehler_VLD, required-interface=IF_DCDC_NV_Komponentenfehler_VLD
      RP_IF_DW_Kilometerstand_XIX_BMC_HV: nonqueued-receiver-com-spec=data-element=DE_DW_Kilometerstand, required-interface=IF_DW_Kilometerstand
      RP_IF_EKK_HVK_EoHVL_Status_XIX_BMC_HV: nonqueued-receiver-com-spec=data-element=DE_EKK_HVK_EoHVL_Status, required-interface=IF_EKK_HVK_EoHVL_Status
      RP_IF_HVEM_BMC_CHA_Wunschleistung_02_XIX_BMC_HV: nonqueued-receiver-com-spec=data-element=DE_HVEM_BMC_CHA_Wunschleistung_02, required-interface=IF_HVEM_BMC_CHA_Wunschleistung_02
      RP_IF_HVEM_BMC_CHA_Wunschleistung_XIX_BMC_HV: nonqueued-receiver-com-spec=data-element=DE_HVEM_BMC_CHA_Wunschleistung, required-interface=IF_HVEM_BMC_CHA_Wunschleistung
      RP_IF_HVEM_MMTR_State_XIX_BMC_HV: nonqueued-receiver-com-spec=data-element=DE_HVEM_MMTR_State, required-interface=IF_HVEM_MMTR_State
      RP_IF_HVEM_SystemMinLeistungsgrenze_XIX_BMC_HV: nonqueued-receiver-com-spec=data-element=DE_HVEM_SystemMinLeistungsgrenze, required-interface=IF_HVEM_SystemMinLeistungsgrenze
      RP_IF_HVLE_IstSpannung_HV_XIX_BMC_HV: nonqueued-receiver-com-spec=data-element=DE_HVLE_IstSpannung_HV, required-interface=IF_HVLE_IstSpannung_HV
      RP_IF_HVLE_OBG_IstModus_XIX_BMC_HV: nonqueued-receiver-com-spec=data-element=DE_HVLE_OBG_IstModus, required-interface=IF_HVLE_OBG_IstModus
      RP_IF_HVLM_BCAM_Aktiv_XIX_BMC_HV: nonqueued-receiver-com-spec=data-element=DE_HVLM_BCAM_Aktiv, required-interface=IF_HVLM_BCAM_Aktiv
      RP_IF_HVLM_BidiLadeModus_XIX_BMC_HV: nonqueued-receiver-com-spec=data-element=DE_HVLM_BidiLadeModus, required-interface=IF_HVLM_BidiLadeModus
      RP_IF_KST_KL_15_XIX_BMC_HV: nonqueued-receiver-com-spec=data-element=DE_KST_KL_15, required-interface=IF_KST_KL_15
      RP_IF_MM_PropulsionSystemActive_XIX_BMC_HV: nonqueued-receiver-com-spec=data-element=DE_MM_PropulsionSystemActive, required-interface=IF_MM_PropulsionSystemActive
      RP_IF_NM_AWC_FCAB_XIX_BMC_HV: nonqueued-receiver-com-spec=data-element=DE_NM_AWC_FCAB, required-interface=IF_NM_AWC_FCAB
      RP_IF_NM_Gateway_FCAB_XIX_BMC_HV: nonqueued-receiver-com-spec=data-element=DE_NM_Gateway_FCAB, required-interface=IF_NM_Gateway_FCAB
      RP_IF_NM_HVZB_FCAB_XIX_BMC_HV: nonqueued-receiver-com-spec=data-element=DE_NM_HVZB_FCAB, required-interface=IF_NM_HVZB_FCAB
      RP_IF_NM_Ladegeraet_FCAB_XIX_BMC_HV: nonqueued-receiver-com-spec=data-element=DE_NM_Ladegeraet_FCAB, required-interface=IF_NM_Ladegeraet_FCAB
      RP_IF_NM_SACID_1_FCAB_XIX_BMC_HV: nonqueued-receiver-com-spec=data-element=DE_NM_SACID_1_FCAB, required-interface=IF_NM_SACID_1_FCAB
      RP_IF_NM_SACID_2_FCAB_XIX_BMC_HV: nonqueued-receiver-com-spec=data-element=DE_NM_SACID_2_FCAB, required-interface=IF_NM_SACID_2_FCAB
      RP_IF_NVEM_Abschaltstufe_XIX_BMC_HV: nonqueued-receiver-com-spec=data-element=DE_NVEM_Abschaltstufe, required-interface=IF_NVEM_Abschaltstufe
      RP_IF_OBD_Abs_Pedal_Pos_XIX_BMC_HV: nonqueued-receiver-com-spec=data-element=DE_OBD_Abs_Pedal_Pos, required-interface=IF_OBD_Abs_Pedal_Pos
      RP_IF_OBD_Aussen_Temp_gef_XIX_BMC_HV: nonqueued-receiver-com-spec=data-element=DE_OBD_Aussen_Temp_gef, required-interface=IF_OBD_Aussen_Temp_gef
      RP_IF_OBD_Barometric_Pressure_XIX_BMC_HV: nonqueued-receiver-com-spec=data-element=DE_OBD_Barometric_Pressure, required-interface=IF_OBD_Barometric_Pressure
      RP_IF_OBD_Calc_Load_Val_XIX_BMC_HV: nonqueued-receiver-com-spec=data-element=DE_OBD_Calc_Load_Val, required-interface=IF_OBD_Calc_Load_Val
      RP_IF_OBD_ClearMem_Inhibit_XIX_BMC_HV: nonqueued-receiver-com-spec=data-element=DE_OBD_ClearMem_Inhibit, required-interface=IF_OBD_ClearMem_Inhibit
      RP_IF_OBD_Driving_Cycle_XIX_BMC_HV: nonqueued-receiver-com-spec=data-element=DE_OBD_Driving_Cycle, required-interface=IF_OBD_Driving_Cycle
      RP_IF_OBD_Eng_Cool_Temp_XIX_BMC_HV: nonqueued-receiver-com-spec=data-element=DE_OBD_Eng_Cool_Temp, required-interface=IF_OBD_Eng_Cool_Temp
      RP_IF_OBD_Engine_RPM_XIX_BMC_HV: nonqueued-receiver-com-spec=data-element=DE_OBD_Engine_RPM, required-interface=IF_OBD_Engine_RPM
      RP_IF_OBD_Kaltstart_Denominator_XIX_BMC_HV: nonqueued-receiver-com-spec=data-element=DE_OBD_Kaltstart_Denominator, required-interface=IF_OBD_Kaltstart_Denominator
      RP_IF_OBD_Minimum_Trip_XIX_BMC_HV: nonqueued-receiver-com-spec=data-element=DE_OBD_Minimum_Trip, required-interface=IF_OBD_Minimum_Trip
      RP_IF_OBD_Normed_Trip_XIX_BMC_HV: nonqueued-receiver-com-spec=data-element=DE_OBD_Normed_Trip, required-interface=IF_OBD_Normed_Trip
      RP_IF_OBD_NumDcyMilOnReq_XIX_BMC_HV: nonqueued-receiver-com-spec=data-element=DE_OBD_NumDcyMilOnReq, required-interface=IF_OBD_NumDcyMilOnReq
      RP_IF_OBD_QBit_Aussen_Temp_XIX_BMC_HV: nonqueued-receiver-com-spec=data-element=DE_OBD_QBit_Aussen_Temp, required-interface=IF_OBD_QBit_Aussen_Temp
      RP_IF_OBD_Sperrung_IUMPR_XIX_BMC_HV: nonqueued-receiver-com-spec=data-element=DE_OBD_Sperrung_IUMPR, required-interface=IF_OBD_Sperrung_IUMPR
      RP_IF_OBD_Sperrung_Kaltstart_Denom_XIX_BMC_HV: nonqueued-receiver-com-spec=data-element=DE_OBD_Sperrung_Kaltstart_Denom, required-interface=IF_OBD_Sperrung_Kaltstart_Denom
      RP_IF_OBD_Typ_XIX_BMC_HV: nonqueued-receiver-com-spec=data-element=DE_OBD_Typ, required-interface=IF_OBD_Typ
      RP_IF_OBD_Warm_Up_Cycle_XIX_BMC_HV: nonqueued-receiver-com-spec=data-element=DE_OBD_Warm_Up_Cycle, required-interface=IF_OBD_Warm_Up_Cycle
      RP_IF_OBDProtocol_req_XIX_BMC_HV: nonqueued-receiver-com-spec=data-element=DE_OBDProtocol_req, required-interface=IF_OBDProtocol_req
      RP_IF_ORU_Status_XIX_BMC_HV: nonqueued-receiver-com-spec=data-element=DE_ORU_Status, required-interface=IF_ORU_Status
      RP_IF_OTP_Aussen_Temp_OBD_XIX_BMC_HV: nonqueued-receiver-com-spec=data-element=DE_OTP_Aussen_Temp_OBD, required-interface=IF_OTP_Aussen_Temp_OBD
      RP_IF_OTP_Aussen_Temp_ungef_XIX_BMC_HV: nonqueued-receiver-com-spec=data-element=DE_OTP_Aussen_Temp_ungef, required-interface=IF_OTP_Aussen_Temp_ungef
      RP_IF_PCM_BMC_VTD_Freeze_Req_XIX_BMC_HV: nonqueued-receiver-com-spec=data-element=DE_PCM_BMC_VTD_Freeze_Req, required-interface=IF_PCM_BMC_VTD_Freeze_Req
      RP_IF_PCM_BMC_VTD_LifeTimeReset_Req_XIX_BMC_HV: nonqueued-receiver-com-spec=data-element=DE_PCM_BMC_VTD_LifeTimeReset_Req, required-interface=IF_PCM_BMC_VTD_LifeTimeReset_Req
      RP_IF_PCM_BMC_VTD_LifeTimeReset_Resp_XIX_BMC_HV: nonqueued-receiver-com-spec=data-element=DE_PCM_BMC_VTD_LifeTimeReset_Resp, required-interface=IF_PCM_BMC_VTD_LifeTimeReset_Resp
      RP_IF_PCM_BMC_VTD_RecentReset_Req_XIX_BMC_HV: nonqueued-receiver-com-spec=data-element=DE_PCM_BMC_VTD_RecentReset_Req, required-interface=IF_PCM_BMC_VTD_RecentReset_Req
      RP_IF_SG_BJB_{10..13}_XIX_BMC_HV: nonqueued-receiver-com-spec=data-element=DE_SG_BJB_{10..13}, required-interface=IF_SG_BJB_{10..13}
      RP_IF_SG_HVK_03_XIX_BMC_HV: nonqueued-receiver-com-spec=data-element=DE_SG_HVK_03, required-interface=IF_SG_HVK_03
      RP_IF_SG_HVLM_14_XIX_BMC_HV: nonqueued-receiver-com-spec=data-element=DE_SG_HVLM_14, required-interface=IF_SG_HVLM_14
      RP_IF_SG_KS_Hybrid_01_Challenge_M_XIX_BMC_HV: nonqueued-receiver-com-spec=data-element=DE_SG_KS_Hybrid_01_Challenge_M, required-interface=IF_SG_KS_Hybrid_01_Challenge_M
      RP_IF_SG_KS_Hybrid_01_Response_M_XIX_BMC_HV: nonqueued-receiver-com-spec=data-element=DE_SG_KS_Hybrid_01_Response_M, required-interface=IF_SG_KS_Hybrid_01_Response_M
      RP_IF_SG_ORU_Control_A_01_XIX_BMC_HV: nonqueued-receiver-com-spec=data-element=DE_SG_ORU_Control_A_01, required-interface=IF_SG_ORU_Control_A_01
      RP_IF_SG_ORU_Control_D_01_XIX_BMC_HV: nonqueued-receiver-com-spec=data-element=DE_SG_ORU_Control_D_01, required-interface=IF_SG_ORU_Control_D_01
      RP_IF_SG_OTAMC_D_01_XIX_BMC_HV: nonqueued-receiver-com-spec=data-element=DE_SG_OTAMC_D_01, required-interface=IF_SG_OTAMC_D_01
      RP_IF_SG_UI1_01_XIX_BMC_HV: nonqueued-receiver-com-spec=data-element=DE_SG_UI1_01, required-interface=IF_SG_UI1_01
      RP_IF_SG_UI1_02_XIX_BMC_HV: nonqueued-receiver-com-spec=data-element=DE_SG_UI1_02, required-interface=IF_SG_UI1_02
      RP_IF_SG_UI2_{01..03}_XIX_BMC_HV: nonqueued-receiver-com-spec=data-element=DE_SG_UI2_{01..03}, required-interface=IF_SG_UI2_{01..03}
      RP_IF_SI_NWDF_30_XIX_BMC_HV: nonqueued-receiver-com-spec=data-element=DE_SI_NWDF_30, required-interface=IF_SI_NWDF_30
      RP_IF_SI_NWDF_XIX_BMC_HV: nonqueued-receiver-com-spec=data-element=DE_SI_NWDF, required-interface=IF_SI_NWDF
      RP_IF_SI_P_Mode_gueltig_XIX_BMC_HV: nonqueued-receiver-com-spec=data-element=DE_SI_P_Mode_gueltig, required-interface=IF_SI_P_Mode_gueltig
      RP_IF_SI_P_Mode_XIX_BMC_HV: nonqueued-receiver-com-spec=data-element=DE_SI_P_Mode, required-interface=IF_SI_P_Mode
      RP_IF_SI_T_Mode_XIX_BMC_HV: nonqueued-receiver-com-spec=data-element=DE_SI_T_Mode, required-interface=IF_SI_T_Mode
      RP_IF_SOK_ungeschuetzte_Zeit_XIX_BMC_HV: nonqueued-receiver-com-spec=data-element=DE_SOK_ungeschuetzte_Zeit, required-interface=IF_SOK_ungeschuetzte_Zeit
      RP_IF_SOK_Zeit_Hybrid_01_Zeit_XIX_BMC_HV: nonqueued-receiver-com-spec=data-element=DE_SOK_Zeit_Hybrid_01_Zeit, required-interface=IF_SOK_Zeit_Hybrid_01_Zeit
      RP_IF_TME_Batt_Kond_Verf_XIX_BMC_HV: nonqueued-receiver-com-spec=data-element=DE_TME_Batt_Kond_Verf, required-interface=IF_TME_Batt_Kond_Verf
      RP_IF_TME_Therm_IstLeistung_HVBatterie_XIX_BMC_HV: nonqueued-receiver-com-spec=data-element=DE_TME_Therm_IstLeistung_HVBatterie, required-interface=IF_TME_Therm_IstLeistung_HVBatterie
      RP_IF_UH_Jahr_XIX_BMC_HV: nonqueued-receiver-com-spec=data-element=DE_UH_Jahr, required-interface=IF_UH_Jahr
      RP_IF_UH_Minute_XIX_BMC_HV: nonqueued-receiver-com-spec=data-element=DE_UH_Minute, required-interface=IF_UH_Minute
      RP_IF_UH_Monat_XIX_BMC_HV: nonqueued-receiver-com-spec=data-element=DE_UH_Monat, required-interface=IF_UH_Monat
      RP_IF_UH_Sekunde_XIX_BMC_HV: nonqueued-receiver-com-spec=data-element=DE_UH_Sekunde, required-interface=IF_UH_Sekunde
      RP_IF_UH_Stunde_XIX_BMC_HV: nonqueued-receiver-com-spec=data-element=DE_UH_Stunde, required-interface=IF_UH_Stunde
      RP_IF_UH_Tag_XIX_BMC_HV: nonqueued-receiver-com-spec=data-element=DE_UH_Tag, required-interface=IF_UH_Tag
      RP_IF_UI1_Iso_Neg_XIX_BMC_HV: nonqueued-receiver-com-spec=data-element=DE_UI1_Iso_Neg, required-interface=IF_UI1_Iso_Neg
      RP_IF_UI1_Iso_Pos_XIX_BMC_HV: nonqueued-receiver-com-spec=data-element=DE_UI1_Iso_Pos, required-interface=IF_UI1_Iso_Pos
      RP_IF_UI1_Iso_Status_XIX_BMC_HV: nonqueued-receiver-com-spec=data-element=DE_UI1_Iso_Status, required-interface=IF_UI1_Iso_Status
      RP_IF_UI1_KompFehlerModus2_{01..26}_XIX_BMC_HV: nonqueued-receiver-com-spec=data-element=DE_UI1_KompFehlerModus2_{01..26}, required-interface=IF_UI1_KompFehlerModus2_{01..26}
      RP_IF_UI1_KompFehlerModus4_{01..16}_XIX_BMC_HV: nonqueued-receiver-com-spec=data-element=DE_UI1_KompFehlerModus4_{01..16}, required-interface=IF_UI1_KompFehlerModus4_{01..16}
      RP_IF_UI1_Spannung{4..6}_XIX_BMC_HV: nonqueued-receiver-com-spec=data-element=DE_UI1_Spannung{4..6}, required-interface=IF_UI1_Spannung{4..6}
      RP_IF_UI1_Status_XIX_BMC_HV: nonqueued-receiver-com-spec=data-element=DE_UI1_Status, required-interface=IF_UI1_Status
      RP_IF_UI1_Stromintegral_Entladen_XIX_BMC_HV: nonqueued-receiver-com-spec=data-element=DE_UI1_Stromintegral_Entladen, required-interface=IF_UI1_Stromintegral_Entladen
      RP_IF_UI1_Stromintegral_Laden_XIX_BMC_HV: nonqueued-receiver-com-spec=data-element=DE_UI1_Stromintegral_Laden, required-interface=IF_UI1_Stromintegral_Laden
      RP_IF_UI1_Temperatur_1_XIX_BMC_HV: nonqueued-receiver-com-spec=data-element=DE_UI1_Temperatur_1, required-interface=IF_UI1_Temperatur_1
      RP_IF_UI1_Temperatur_2_XIX_BMC_HV: nonqueued-receiver-com-spec=data-element=DE_UI1_Temperatur_2, required-interface=IF_UI1_Temperatur_2
      RP_IF_UI2_KompFehlerModus2_{01..26}_XIX_BMC_HV: nonqueued-receiver-com-spec=data-element=DE_UI2_KompFehlerModus2_{01..26}, required-interface=IF_UI2_KompFehlerModus2_{01..26}
      RP_IF_UI2_KompFehlerModus4_{01..16}_XIX_BMC_HV: nonqueued-receiver-com-spec=data-element=DE_UI2_KompFehlerModus4_{01..16}, required-interface=IF_UI2_KompFehlerModus4_{01..16}
      RP_IF_UI2_Status_XIX_BMC_HV: nonqueued-receiver-com-spec=data-element=DE_UI2_Status, required-interface=IF_UI2_Status
      RP_IF_UI2_Stromintegral_Entladen_XIX_BMC_HV: nonqueued-receiver-com-spec=data-element=DE_UI2_Stromintegral_Entladen, required-interface=IF_UI2_Stromintegral_Entladen
      RP_IF_UI2_Stromintegral_Laden_XIX_BMC_HV: nonqueued-receiver-com-spec=data-element=DE_UI2_Stromintegral_Laden, required-interface=IF_UI2_Stromintegral_Laden
      RP_IF_UI2_Temperatur_1_XIX_BMC_HV: nonqueued-receiver-com-spec=data-element=DE_UI2_Temperatur_1, required-interface=IF_UI2_Temperatur_1
      RP_IF_UI2_Temperatur_2_XIX_BMC_HV: nonqueued-receiver-com-spec=data-element=DE_UI2_Temperatur_2, required-interface=IF_UI2_Temperatur_2
      RP_IF_UI2Sens01_CALID_Index_{01..16}_XIX_BMC_HV: nonqueued-receiver-com-spec=data-element=DE_UI2Sens01_CALID_Index_{01..16}, required-interface=IF_UI2Sens01_CALID_Index_{01..16}
      RP_IF_UI2Sens01_CVN_Byte_{1..4}_XIX_BMC_HV: nonqueued-receiver-com-spec=data-element=DE_UI2Sens01_CVN_Byte_{1..4}, required-interface=IF_UI2Sens01_CVN_Byte_{1..4}
      RP_IF_UI2Sens01_CVN_VLD_XIX_BMC_HV: nonqueued-receiver-com-spec=data-element=DE_UI2Sens01_CVN_VLD, required-interface=IF_UI2Sens01_CVN_VLD
      RP_IF_UI2Sens01_ErrMem_State_XIX_BMC_HV: nonqueued-receiver-com-spec=data-element=DE_UI2Sens01_ErrMem_State, required-interface=IF_UI2Sens01_ErrMem_State
      RP_IF_UI2Sens02_CALID_Index_{01..16}_XIX_BMC_HV: nonqueued-receiver-com-spec=data-element=DE_UI2Sens02_CALID_Index_{01..16}, required-interface=IF_UI2Sens02_CALID_Index_{01..16}
      RP_IF_UI2Sens02_CVN_Byte_{1..4}_XIX_BMC_HV: nonqueued-receiver-com-spec=data-element=DE_UI2Sens02_CVN_Byte_{1..4}, required-interface=IF_UI2Sens02_CVN_Byte_{1..4}
      RP_IF_UI2Sens02_CVN_VLD_XIX_BMC_HV: nonqueued-receiver-com-spec=data-element=DE_UI2Sens02_CVN_VLD, required-interface=IF_UI2Sens02_CVN_VLD
      RP_IF_UI2Sens02_ErrMem_State_XIX_BMC_HV: nonqueued-receiver-com-spec=data-element=DE_UI2Sens02_ErrMem_State, required-interface=IF_UI2Sens02_ErrMem_State
      RP_IF_VDSO_Vx3d_XIX_BMC_HV: nonqueued-receiver-com-spec=data-element=DE_VDSO_Vx3d, required-interface=IF_VDSO_Vx3d
      RP_IF_VIN_{10..17}_XIX_BMC_HV: nonqueued-receiver-com-spec=data-element=DE_VIN_{10..17}, required-interface=IF_VIN_{10..17}
      RP_IF_VIN_{1..9}_XIX_BMC_HV: nonqueued-receiver-com-spec=data-element=DE_VIN_{1..9}, required-interface=IF_VIN_{1..9}
      RP_IF_ZM_HV_Auszeit_HiRes_XIX_BMC_HV: nonqueued-receiver-com-spec=data-element=DE_ZM_HV_Auszeit_HiRes, required-interface=IF_ZM_HV_Auszeit_HiRes
      RP_IF_ZM_HV_Auszeit_Status_XIX_BMC_HV: nonqueued-receiver-com-spec=data-element=DE_ZM_HV_Auszeit_Status, required-interface=IF_ZM_HV_Auszeit_Status
      RP_IF_ZM_HV_Auszeit_XIX_BMC_HV: nonqueued-receiver-com-spec=data-element=DE_ZM_HV_Auszeit, required-interface=IF_ZM_HV_Auszeit
    provide port SG_BMC_HV_13: nonqueued-sender-com-spec{data-element=SG_BMC_HV_13, init-value=fields=[BMC_HV_13_BZ:0, BMC_HV_13_CRC:0, BMC_Unterspannungszaehler_CMC01:510, BMC_Unterspannungszaehler_CMC02:510, BMC_Unterspannungszaehler_CMC03:510, BMC_Unterspannungszaehler_CMC04:510, SignalVoid_BMC_HV_13_0:0, SignalVoid_BMC_HV_13_1:0]}, provided-interface=SG_BMC_HV_13
    require port SG_UI1_01: nonqueued-receiver-com-spec{data-element=SG_UI1_01, init-value=fields=[SignalVoid_UI1_01_0:0, SignalVoid_UI1_01_1:0, SignalVoid_UI1_01_2:0, UI1_KL30_Spannung:254, UI1_Strom:1048574, UISensorIso_01_BZ:0, UISensorIso_01_CRC:0]}, required-interface=SG_UI1_01
    require port BJB_ErrMem_State: nonqueued-receiver-com-spec{data-element=BJB_ErrMem_State, init-value=2}, required-interface=BJB_ErrMem_State
    require port BJB_ErrMem_State_1: nonqueued-receiver-com-spec{data-element=BJB_ErrMem_State, init-value=2}, required-interface=BJB_ErrMem_State_1
    9 x provide port:
      SP_IF_KN_Hybrid_01_ECUKnockOutTimer_XIX_Infrastructure_Hybrid_01_XIX_network_infrastructure_XIX_BMC_HV: provided-interface=IF_KN_Hybrid_01_ECUKnockOutTimer
      SP_IF_KN_Hybrid_01_BusKnockOut_XIX_Infrastructure_Hybrid_01_XIX_network_infrastructure_XIX_BMC_HV: provided-interface=IF_KN_Hybrid_01_BusKnockOut
      SP_IF_KN_Hybrid_01_ECUKnockOut_XIX_Infrastructure_Hybrid_01_XIX_network_infrastructure_XIX_BMC_HV: provided-interface=IF_KN_Hybrid_01_ECUKnockOut
      SP_IF_KN_Hybrid_01_BusKnockOutTimer_XIX_Infrastructure_Hybrid_01_XIX_network_infrastructure_XIX_BMC_HV: provided-interface=IF_KN_Hybrid_01_BusKnockOutTimer
      SP_IF_NM_Hybrid_01_NM_aktiv_Diag_XIX_Infrastructure_Hybrid_01_XIX_network_infrastructure_XIX_BMC_HV: provided-interface=IF_NM_Hybrid_01_NM_aktiv_Diag
      SP_IF_NM_Hybrid_01_UDS_CC_XIX_Infrastructure_Hybrid_01_XIX_network_infrastructure_XIX_BMC_HV: provided-interface=IF_NM_Hybrid_01_UDS_CC
      SP_IF_NM_Hybrid_01_CBV_CRI_XIX_Infrastructure_Hybrid_01_XIX_network_infrastructure_XIX_BMC_HV: provided-interface=IF_NM_Hybrid_01_CBV_CRI
      SP_IF_NM_Hybrid_01_NM_aktiv_Tmin_XIX_Infrastructure_Hybrid_01_XIX_network_infrastructure_XIX_BMC_HV: provided-interface=IF_NM_Hybrid_01_NM_aktiv_Tmin
      SP_IF_NM_Hybrid_01_NM_aktiv_KL15_XIX_Infrastructure_Hybrid_01_XIX_network_infrastructure_XIX_BMC_HV: provided-interface=IF_NM_Hybrid_01_NM_aktiv_KL15
    require port RP_IF_DEV_Hybrid_01_Req_00_FD_Data_XIX_Infrastructure_Hybrid_01_XIX_network_infrastructure_XIX_BMC_HV: required-interface=IF_DEV_Hybrid_01_Req_00_FD_Data
    6 x provide port:
      SP_IF_DEV_Hybrid_01_Resp_FF_FD_Data_XIX_Infrastructure_Hybrid_01_XIX_network_infrastructure_XIX_BMC_HV: provided-interface=IF_DEV_Hybrid_01_Resp_FF_FD_Data
      SP_IF_NM_Hybrid_01_Wakeup_V12_XIX_Infrastructure_Hybrid_01_XIX_network_infrastructure_XIX_BMC_HV: provided-interface=IF_NM_Hybrid_01_Wakeup_V12
      SP_IF_NM_aktiv_Konditionierungsbedarf_XIX_Infrastructure_Hybrid_01_XIX_network_infrastructure_XIX_BMC_HV: provided-interface=IF_NM_aktiv_Konditionierungsbedarf
      SP_IF_NM_Hybrid_01_Lokalaktiv_XIX_Infrastructure_Hybrid_01_XIX_network_infrastructure_XIX_BMC_HV: provided-interface=IF_NM_Hybrid_01_Lokalaktiv
      SP_IF_NM_Hybrid_01_Subsystemaktiv_XIX_Infrastructure_Hybrid_01_XIX_network_infrastructure_XIX_BMC_HV: provided-interface=IF_NM_Hybrid_01_Subsystemaktiv
      SP_IF_NM_aktiv_SubbusSteuerung_BMC_HV_XIX_Infrastructure_Hybrid_01_XIX_network_infrastructure_XIX_BMC_HV: provided-interface=IF_NM_aktiv_SubbusSteuerung_BMC_HV
    require port RP_IF_ISO_ALL_01_Req_Data_XIX_diagnosis_infrastructure_Hybrid_01_XIX_diagnosis_infrastructure_XIX_BMC_HV: required-interface=IF_ISO_ALL_01_Req_Data
    provide port SP_IF_ISO_ALL_01_Req_Data_XIX_diagnosis_infrastructure_Hybrid_01_XIX_diagnosis_infrastructure_XIX_BMC_HV: provided-interface=IF_ISO_ALL_01_Req_Data
    provide port SP_IF_Hybrid_01_KompSchutz_XIX_KS_BMC_HV_XIX_KSGen3_XIX_BMC_HV: provided-interface=IF_Hybrid_01_KompSchutz
    provide port SG_BMC_HV_12: nonqueued-sender-com-spec{data-element=SG_BMC_HV_12, init-value=fields=[BMC_HV_12_BZ:0, BMC_HV_12_CRC:0, BMC_Sperrung_Uebertemperatur:2, BMC_Ueberspannungszaehler_CMC03:510, BMC_Ueberspannungszaehler_CMC04:510, BMC_Uebertemperaturzaehler_CMC03:65534, BMC_Uebertemperaturzaehler_CMC04:65534]}, provided-interface=SG_BMC_HV_12
    require port AB_Deaktivierung_HV: nonqueued-receiver-com-spec{data-element=AB_Deaktivierung_HV, init-value=0}, required-interface=AB_Deaktivierung_HV
    11 x provide port:
      SG_BMC_HV_11: nonqueued-sender-com-spec{data-element=SG_BMC_HV_11, init-value=fields=[BMC_HV_11_BZ:0, BMC_HV_11_CRC:0, BMC_Sperrung_Ueberspannung:2, BMC_Ueberspannungszaehler_CMC01:510, BMC_Ueberspannungszaehler_CMC02:510, BMC_Uebertemperaturzaehler_CMC01:65534, BMC_Uebertemperaturzaehler_CMC02:65534]}, provided-interface=SG_BMC_HV_11
      SG_BMC_HV_14: nonqueued-sender-com-spec{data-element=SG_BMC_HV_11, init-value=fields=[BMC_HV_11_BZ:0, BMC_HV_11_CRC:0, BMC_Sperrung_Ueberspannung:2, BMC_Ueberspannungszaehler_CMC01:510, BMC_Ueberspannungszaehler_CMC02:510, BMC_Uebertemperaturzaehler_CMC01:65534, BMC_Uebertemperaturzaehler_CMC02:65534]}, provided-interface=SG_BMC_HV_14
      SG_BMC_HV_15: nonqueued-sender-com-spec{data-element=SG_BMC_HV_11, init-value=fields=[BMC_HV_11_BZ:0, BMC_HV_11_CRC:0, BMC_Sperrung_Ueberspannung:2, BMC_Ueberspannungszaehler_CMC01:510, BMC_Ueberspannungszaehler_CMC02:510, BMC_Uebertemperaturzaehler_CMC01:65534, BMC_Uebertemperaturzaehler_CMC02:65534]}, provided-interface=SG_BMC_HV_15
      SG_BMC_HV_10: nonqueued-sender-com-spec{data-element=SG_BMC_HV_10, init-value=fields=[BMC_Datenuebernahme_Anf:0, BMC_HV_10_BZ:0, BMC_HV_10_CRC:0, BMC_Lebensdauer_Trennelemente:131070, BMC_Sperrung_Unterspannung:2, BMC_Status_HV_Spannungssensorik:0, BMC_Status_Trennelemente:6, SignalVoid_BMC_HV_10_0:0, SignalVoid_BMC_HV_10_1:0, SignalVoid_BMC_HV_10_2:0, SignalVoid_BMC_HV_10_3:0]}, provided-interface=SG_BMC_HV_10
      SG_BMC_HV_16: nonqueued-sender-com-spec{data-element=SG_BMC_HV_11, init-value=fields=[BMC_HV_11_BZ:0, BMC_HV_11_CRC:0, BMC_Sperrung_Ueberspannung:2, BMC_Ueberspannungszaehler_CMC01:510, BMC_Ueberspannungszaehler_CMC02:510, BMC_Uebertemperaturzaehler_CMC01:65534, BMC_Uebertemperaturzaehler_CMC02:65534]}, provided-interface=SG_BMC_HV_16
      SG_BMC_HV_04: nonqueued-sender-com-spec{data-element=SG_BMC_HV_04, init-value=fields=[BMC_Dev_Freigabe:0, BMC_Flash_Freigabe:0, BMC_HV_04_BZ:0, BMC_HV_04_CRC:0, BMC_Iso_Mode_Anf:0, BMC_UI1_Spannung1_Schalt_Anf:0, BMC_UI1_Spannung2_Schalt_Anf:0, BMC_UI2_Spannung1_Schalt_Anf:0, BMC_UI2_Spannung2_Schalt_Anf:0, SignalVoid_BMC_HV_04_0:0, SignalVoid_BMC_HV_04_1:0, SignalVoid_BMC_HV_04_2:0, SignalVoid_BMC_HV_04_3:0, SignalVoid_BMC_HV_04_4:0, SignalVoid_BMC_HV_04_5:0]}, provided-interface=SG_BMC_HV_04
      SG_BMC_HV_01: nonqueued-sender-com-spec{data-element=SG_BMC_HV_01, init-value=fields=[BMC_Bankstatus:14, BMC_HV_01_BZ:0, BMC_HV_01_CRC:0, BMC_HVK_EoHVL_Status:0, BMC_HVK_Fehler_HVIL:3, BMC_HVK_Fehler_Intern:3, BMC_HVK_Fehler_SD:3, BMC_Modus:15, BMC_Spannung:16382, BMC_Spannung_Messzeit:254, BMC_Spannung_ZwischenKreis:16382, BMC_Spannung_ZwischenKreis_2:16382, BMC_Status_Spgfreiheit:0, BMC_Strom:65534, BMC_Strom_02:131070, BMC_Strom_Messzeit:254, SignalVoid_BMC_HV_01_0:0]}, provided-interface=SG_BMC_HV_01
      SG_BMC_HV_02: nonqueued-sender-com-spec{data-element=SG_BMC_HV_02, init-value=fields=[Anzeige_SOC:1022, BMC_AC_Laden:0, BMC_Bank_Notlauf_erlaubt:1, BMC_Bank_parallel_erlaubt:1, BMC_Bank_seriell_erlaubt:1, BMC_DC_Laden:0, BMC_Energie_Sockel_SoC:1022, BMC_Energieinhalt:65534, BMC_Fehler_Leistungsred:0, BMC_Fehler_Warnung:0, BMC_HV_02_BZ:0, BMC_HV_02_CRC:0, BMC_IstZellspannungMax:4094, BMC_IstZellspannungMin:4094, BMC_IWU_Status:0, BMC_IWU_Wert_neg:65534, BMC_IWU_Wert_pos:65534, BMC_Leerlaufspannung:1022, BMC_Max_Entladeleistung:8190, BMC_Max_Entladestrom:8190, BMC_Max_Ladeleistung:8190, BMC_Max_Ladestrom:8190, BMC_MinDyn_Entladespannung:1022, BMC_MinDyn_Ladespannung:1022, BMC_MMTR_Status:14, BMC_NutzbarerSOC:4094, BMC_PerfInd_Entladen:1022, BMC_PerfInd_Laden:1022, BMC_PredLeistung_StuetzungNV:4094, BMC_Spannung_DC_Ladesaeule:32766, BMC_Status_DCLS:0, BMC_TechnischerSOC:2046, BMC_Unterboden_Warnung:0, BMC_Verbauinfo_ACSchuetz:0, BMC_Verbauinfo_Bank:0, BMC_Vorlade_Zielspannung:1022, BMC_ZellTemp_virtuell_max:1022, BMC_ZellTemp_virtuell_min:1022, Hybrid_01_OBD_Lampe_Anf:0, SignalVoid_BMC_HV_02_0:0, SignalVoid_BMC_HV_02_1:0, SignalVoid_BMC_HV_02_2:0, SignalVoid_BMC_HV_02_3:0, SignalVoid_BMC_HV_02_4:0, SignalVoid_BMC_HV_02_5:0]}, provided-interface=SG_BMC_HV_02
      SG_KS_Hybrid_01_Challenge_K: nonqueued-sender-com-spec{data-element=SG_KS_Hybrid_01_Challenge_K, init-value=fields=[KS_Hybrid_01_ChK:8 x 0, KS_Hybrid_01_ChK_IKACtr:0, KS_Hybrid_01_ChK_SID:0]}, provided-interface=SG_KS_Hybrid_01_Challenge_K
      SG_KS_Hybrid_01_ReqFrame: nonqueued-sender-com-spec{data-element=SG_KS_Hybrid_01_ReqFrame, init-value=fields=[KS_Hybrid_01_Req_ErrCtr:0, KS_Hybrid_01_Req_IKA_Retry:0, KS_Hybrid_01_Req_Prio:0, KS_Hybrid_01_Req_SID:0, KS_Hybrid_01_Req_SWMaj:0, KS_Hybrid_01_Req_SWMin:0, KS_Hybrid_01_Req_SWPat:0, KS_Hybrid_01_Req_VKMS_Err:0]}, provided-interface=SG_KS_Hybrid_01_ReqFrame
      SG_KS_Hybrid_01_Response_K: nonqueued-sender-com-spec{data-element=SG_KS_Hybrid_01_Response_K, init-value=fields=[KS_Hybrid_01_ReK:8 x 0, KS_Hybrid_01_ReK_IKACtr:0, KS_Hybrid_01_ReK_SID:0]}, provided-interface=SG_KS_Hybrid_01_Response_K
    require port SG_BJB_11: nonqueued-receiver-com-spec{data-element=SG_BJB_11, init-value=fields=[BJB_11_BZ:0, BJB_11_CRC:0, BJB_Sperrung_Ueberspannung:2, BJB_Ueberspannungszaehler_CMC01:510, BJB_Ueberspannungszaehler_CMC02:510, BJB_Uebertemperaturzaehler_CMC01:65534, BJB_Uebertemperaturzaehler_CMC02:65534]}, required-interface=SG_BJB_11
    provide port SG_BMC_HV_18: nonqueued-sender-com-spec{data-element=SG_BMC_HV_10, init-value=fields=[BMC_Datenuebernahme_Anf:0, BMC_HV_10_BZ:0, BMC_HV_10_CRC:0, BMC_Lebensdauer_Trennelemente:131070, BMC_Sperrung_Unterspannung:2, BMC_Status_HV_Spannungssensorik:0, BMC_Status_Trennelemente:6, SignalVoid_BMC_HV_10_0:0, SignalVoid_BMC_HV_10_1:0, SignalVoid_BMC_HV_10_2:0, SignalVoid_BMC_HV_10_3:0]}, provided-interface=SG_BMC_HV_17
    6 x require port:
      SG_BJB_10: nonqueued-receiver-com-spec{data-element=SG_BJB_10, init-value=fields=[BJB_10_BZ:0, BJB_10_CRC:0, BJB_Lebensdauer_Trennelemente:131070, BJB_Sperrung_Unterspannung:2, BJB_Status_HV_Spannungssensorik:0, BJB_Status_Trennelemente:6, SignalVoid_BJB_10_0:0, SignalVoid_BJB_10_1:0, SignalVoid_BJB_10_2:0, SignalVoid_BJB_10_3:0]}, required-interface=SG_BJB_10
      SG_BJB_{12..14}: nonqueued-receiver-com-spec{data-element=SG_BJB_11, init-value=fields=[BJB_11_BZ:0, BJB_11_CRC:0, BJB_Sperrung_Ueberspannung:2, BJB_Ueberspannungszaehler_CMC01:510, BJB_Ueberspannungszaehler_CMC02:510, BJB_Uebertemperaturzaehler_CMC01:65534, BJB_Uebertemperaturzaehler_CMC02:65534]}, required-interface=SG_BJB_{12..14}
      SG_BJB_15: nonqueued-receiver-com-spec{data-element=SG_BJB_12, init-value=fields=[BJB_12_BZ:0, BJB_12_CRC:0, BJB_Sperrung_Uebertemperatur:2, BJB_Ueberspannungszaehler_CMC03:510, BJB_Ueberspannungszaehler_CMC04:510, BJB_Uebertemperaturzaehler_CMC03:65534, BJB_Uebertemperaturzaehler_CMC04:65534]}, required-interface=SG_BJB_15
      SG_BJB_16: nonqueued-receiver-com-spec{data-element=SG_BJB_13, init-value=fields=[BJB_13_BZ:0, BJB_13_CRC:0, BJB_Unterspannungszaehler_CMC01:510, BJB_Unterspannungszaehler_CMC02:510, BJB_Unterspannungszaehler_CMC03:510, BJB_Unterspannungszaehler_CMC04:510, SignalVoid_BJB_13_0:0, SignalVoid_BJB_13_1:0]}, required-interface=SG_BJB_16
    10 x provide port:
      SG_BMC_HV_5: nonqueued-sender-com-spec{data-element=SG_BMC_HV_04, init-value=fields=[BMC_Dev_Freigabe:0, BMC_Flash_Freigabe:0, BMC_HV_04_BZ:0, BMC_HV_04_CRC:0, BMC_Iso_Mode_Anf:0, BMC_UI1_Spannung1_Schalt_Anf:0, BMC_UI1_Spannung2_Schalt_Anf:0, BMC_UI2_Spannung1_Schalt_Anf:0, BMC_UI2_Spannung2_Schalt_Anf:0, SignalVoid_BMC_HV_04_0:0, SignalVoid_BMC_HV_04_1:0, SignalVoid_BMC_HV_04_2:0, SignalVoid_BMC_HV_04_3:0, SignalVoid_BMC_HV_04_4:0, SignalVoid_BMC_HV_04_5:0]}, provided-interface=SG_BMC_HV_5
      SG_BMC_HV_17: nonqueued-sender-com-spec{data-element=SG_BMC_HV_10, init-value=fields=[BMC_Datenuebernahme_Anf:0, BMC_HV_10_BZ:0, BMC_HV_10_CRC:0, BMC_Lebensdauer_Trennelemente:131070, BMC_Sperrung_Unterspannung:2, BMC_Status_HV_Spannungssensorik:0, BMC_Status_Trennelemente:6, SignalVoid_BMC_HV_10_0:0, SignalVoid_BMC_HV_10_1:0, SignalVoid_BMC_HV_10_2:0, SignalVoid_BMC_HV_10_3:0]}, provided-interface=SG_BMC_HV_18
      SG_BMC_HV_19: nonqueued-sender-com-spec{data-element=SG_BMC_HV_11, init-value=fields=[BMC_HV_11_BZ:0, BMC_HV_11_CRC:0, BMC_Sperrung_Ueberspannung:2, BMC_Ueberspannungszaehler_CMC01:510, BMC_Ueberspannungszaehler_CMC02:510, BMC_Uebertemperaturzaehler_CMC01:65534, BMC_Uebertemperaturzaehler_CMC02:65534]}, provided-interface=SG_BMC_HV_19
      SG_BMC_HV_20: nonqueued-sender-com-spec{data-element=SG_BMC_HV_12, init-value=fields=[BMC_HV_12_BZ:0, BMC_HV_12_CRC:0, BMC_Sperrung_Uebertemperatur:2, BMC_Ueberspannungszaehler_CMC03:510, BMC_Ueberspannungszaehler_CMC04:510, BMC_Uebertemperaturzaehler_CMC03:65534, BMC_Uebertemperaturzaehler_CMC04:65534]}, provided-interface=SG_BMC_HV_20
      SG_BMC_HV_21: nonqueued-sender-com-spec{data-element=SG_BMC_HV_13, init-value=fields=[BMC_HV_13_BZ:0, BMC_HV_13_CRC:0, BMC_Unterspannungszaehler_CMC01:510, BMC_Unterspannungszaehler_CMC02:510, BMC_Unterspannungszaehler_CMC03:510, BMC_Unterspannungszaehler_CMC04:510, SignalVoid_BMC_HV_13_0:0, SignalVoid_BMC_HV_13_1:0]}, provided-interface=SG_BMC_HV_21
      Vishnu_Test_100Bytes_PDU_NewSignal1_37542d23452fe910: nonqueued-sender-com-spec=Vishnu_Test_100Bytes_PDU_NewSignal1_37542d23452fe910, provided-interface=Vishnu_Test_100Bytes_PDU_NewSignal1_37542d23452fe910
      Vishnu_Test_100Bytes_PDU_NewSignal2_302017e93d94206c: nonqueued-sender-com-spec=Vishnu_Test_100Bytes_PDU_NewSignal2_302017e93d94206c, provided-interface=Vishnu_Test_100Bytes_PDU_NewSignal2_302017e93d94206c
      Vishnu_Test_100Bytes_PDU_NewSignal3_ebd34b418955d5b1: nonqueued-sender-com-spec=Vishnu_Test_100Bytes_PDU_NewSignal3_ebd34b418955d5b1, provided-interface=Vishnu_Test_100Bytes_PDU_NewSignal3_ebd34b418955d5b1
      Vishnu_Test_100Bytes_PDU_NewSignal4_21c239f862026de9: nonqueued-sender-com-spec=Vishnu_Test_100Bytes_PDU_NewSignal4_21c239f862026de9, provided-interface=Vishnu_Test_100Bytes_PDU_NewSignal4_21c239f862026de9
      Vishnu_Test_100Bytes_PDU_NewSignal5_2a9e79b5a4a81ebd: nonqueued-sender-com-spec=Vishnu_Test_100Bytes_PDU_NewSignal5_2a9e79b5a4a81ebd, provided-interface=Vishnu_Test_100Bytes_PDU_NewSignal5_2a9e79b5a4a81ebd
    require port DTC_Test_PDU_Set_Signal_e68158b3301efab7: nonqueued-receiver-com-spec=data-element=DTC_Test_PDU_Set_Signal_e68158b3301efab7, required-interface=DTC_Test_PDU_Set_Signal_e68158b3301efab7
    21 x component:
      ServiceControl: type=ServiceControl
      RT_VehComm: type=RT_VehComm
      BMC_Berechnung_SOC_XIX_SoC_XIX_BMC_HV: type=BMC_Berechnung_SOC_XIX_SoC_XIX_BMC_HV
      BMC_HVS_Slave_XIX_SoC_XIX_BMC_HV: type=BMC_HVS_Slave_XIX_SoC_XIX_BMC_HV
      BMC_HV_Netzsteuerung_XIX_NV_SD_XIX_BMC_HV: type=BMC_HV_Netzsteuerung_XIX_NV_SD_XIX_BMC_HV
      BMC_SafetyDataStorage_XIX_SoC_XIX_BMC_HV: type=BMC_SafetyDataStorage_XIX_SoC_XIX_BMC_HV
      DaapServer_BMC_HV_XIX_GDC_DAAP_XIX_BMC_HV: type=DaapServer_BMC_HV_XIX_GDC_DAAP_XIX_BMC_HV
      HVB_Fehlerausgabe_SecondaryOBDECU_XIX_SoC_XIX_BMC_HV: type=HVB_Fehlerausgabe_SecondaryOBDECU_XIX_SoC_XIX_BMC_HV
      HV_Batterie_RTM_XIX_RTM_XIX_BMC_HV: type=HV_Batterie_RTM_XIX_RTM_XIX_BMC_HV
      HochvoltBatterieManagement_XIX_SoC_XIX_BMC_HV: type=HochvoltBatterieManagement_XIX_SoC_XIX_BMC_HV
      Infrastructure_Hybrid_01_XIX_network_infrastructure_XIX_BMC_HV: type=Infrastructure_Hybrid_01_XIX_network_infrastructure_XIX_BMC_HV
      KS_BMC_HV_XIX_KSGen3_XIX_BMC_HV: type=KS_BMC_HV_XIX_KSGen3_XIX_BMC_HV
      ORU_Infrastructure_Hybrid_01_XIX_ORU6_XIX_BMC_HV: type=ORU_Infrastructure_Hybrid_01_XIX_ORU6_XIX_BMC_HV
      OTA_Infrastructure_Hybrid_01_XIX_ORU6_XIX_BMC_HV: type=OTA_Infrastructure_Hybrid_01_XIX_ORU6_XIX_BMC_HV
      SOK_Participant_BMC_HV_XIX_SOK_XIX_BMC_HV: type=SOK_Participant_BMC_HV_XIX_SOK_XIX_BMC_HV
      VKMS_Participant_BMC_HV_XIX_VKMS_XIX_BMC_HV: type=VKMS_Participant_BMC_HV_XIX_VKMS_XIX_BMC_HV
      diagnosis_infrastructure_Hybrid_01_XIX_diagnosis_infrastructure_XIX_BMC_HV: type=diagnosis_infrastructure_Hybrid_01_XIX_diagnosis_infrastructure_XIX_BMC_HV
      Ivd: type=Ivd
      BAPConfig: type=BAPConfig
      ctASG_LSG1: type=ctASG_LSG1
      RT_Vishnu: type=RT_Vishnu
    delegate HochvoltBatterieManagement_XIX_SoC_XIX_BMC_HV.RP_IF_AB_Deaktivierung_HV_XIX_HochvoltBatterieManagement_XIX_SoC_XIX_BMC_HV <-> outer port RP_IF_AB_Deaktivierung_HV_XIX_BMC_HV  # _XIX_AirbagFunctions_XIX_AirbagBasisFunktionen_XIX_Airbag_6D_XIX_HochvoltBatterieManagement_XIX_SoC_XIX_BMC_HV_XIX_AB_Deaktivierung_HV
    delegate BMC_Berechnung_SOC_XIX_SoC_XIX_BMC_HV.SP_IF_Anzeige_SOC_XIX_BMC_Berechnung_SOC_XIX_SoC_XIX_BMC_HV <-> outer port SP_IF_Anzeige_SOC_XIX_BMC_HV
    delegate BMC_HVS_Slave_XIX_SoC_XIX_BMC_HV.SP_IF_BMC_HVK_EoHVL_Status_XIX_BMC_HVS_Slave_XIX_SoC_XIX_BMC_HV <-> outer port SP_IF_BMC_HVK_EoHVL_Status_XIX_BMC_HV
    delegate BMC_HVS_Slave_XIX_SoC_XIX_BMC_HV.SP_IF_BMC_HVK_Fehler_HVIL_XIX_BMC_HVS_Slave_XIX_SoC_XIX_BMC_HV <-> outer port SP_IF_BMC_HVK_Fehler_HVIL_XIX_BMC_HV
    delegate BMC_HVS_Slave_XIX_SoC_XIX_BMC_HV.SP_IF_BMC_HVK_Fehler_Intern_XIX_BMC_HVS_Slave_XIX_SoC_XIX_BMC_HV <-> outer port SP_IF_BMC_HVK_Fehler_Intern_XIX_BMC_HV
    delegate BMC_HVS_Slave_XIX_SoC_XIX_BMC_HV.SP_IF_BMC_HVK_Fehler_SD_XIX_BMC_HVS_Slave_XIX_SoC_XIX_BMC_HV <-> outer port SP_IF_BMC_HVK_Fehler_SD_XIX_BMC_HV
    delegate BMC_HVS_Slave_XIX_SoC_XIX_BMC_HV.SP_IF_BMC_IWU_Status_XIX_BMC_HVS_Slave_XIX_SoC_XIX_BMC_HV <-> outer port SP_IF_BMC_IWU_Status_XIX_BMC_HV
    delegate BMC_HVS_Slave_XIX_SoC_XIX_BMC_HV.SP_IF_BMC_IWU_Wert_neg_XIX_BMC_HVS_Slave_XIX_SoC_XIX_BMC_HV <-> outer port SP_IF_BMC_IWU_Wert_neg_XIX_BMC_HV
    delegate BMC_HVS_Slave_XIX_SoC_XIX_BMC_HV.SP_IF_BMC_IWU_Wert_pos_XIX_BMC_HVS_Slave_XIX_SoC_XIX_BMC_HV <-> outer port SP_IF_BMC_IWU_Wert_pos_XIX_BMC_HV
    delegate BMC_HVS_Slave_XIX_SoC_XIX_BMC_HV.SP_IF_BMC_Status_Spgfreiheit_XIX_BMC_HVS_Slave_XIX_SoC_XIX_BMC_HV <-> outer port SP_IF_BMC_Status_Spgfreiheit_XIX_BMC_HV
    delegate BMC_HV_Netzsteuerung_XIX_NV_SD_XIX_BMC_HV.SP_IF_BMC_Modus_XIX_BMC_HV_Netzsteuerung_XIX_NV_SD_XIX_BMC_HV <-> outer port SP_IF_BMC_Modus_XIX_BMC_HV
    delegate BMC_HV_Netzsteuerung_XIX_NV_SD_XIX_BMC_HV.SP_IF_BMC_Vorlade_Zielspannung_XIX_BMC_HV_Netzsteuerung_XIX_NV_SD_XIX_BMC_HV <-> outer port SP_IF_BMC_Vorlade_Zielspannung_XIX_BMC_HV
    delegate BMC_SafetyDataStorage_XIX_SoC_XIX_BMC_HV.SP_IF_BMC_Datenuebernahme_Anf_XIX_BMC_SafetyDataStorage_XIX_SoC_XIX_BMC_HV <-> outer port SP_IF_BMC_Datenuebernahme_Anf_XIX_BMC_HV
    delegate BMC_SafetyDataStorage_XIX_SoC_XIX_BMC_HV.SP_IF_BMC_HV_10_BZ_XIX_BMC_SafetyDataStorage_XIX_SoC_XIX_BMC_HV <-> outer port SP_IF_BMC_HV_10_BZ_XIX_BMC_HV
    delegate BMC_SafetyDataStorage_XIX_SoC_XIX_BMC_HV.SP_IF_BMC_HV_10_CRC_XIX_BMC_SafetyDataStorage_XIX_SoC_XIX_BMC_HV <-> outer port SP_IF_BMC_HV_10_CRC_XIX_BMC_HV
    delegate BMC_SafetyDataStorage_XIX_SoC_XIX_BMC_HV.SP_IF_BMC_HV_11_BZ_XIX_BMC_SafetyDataStorage_XIX_SoC_XIX_BMC_HV <-> outer port SP_IF_BMC_HV_11_BZ_XIX_BMC_HV
    delegate BMC_SafetyDataStorage_XIX_SoC_XIX_BMC_HV.SP_IF_BMC_HV_11_CRC_XIX_BMC_SafetyDataStorage_XIX_SoC_XIX_BMC_HV <-> outer port SP_IF_BMC_HV_11_CRC_XIX_BMC_HV
    delegate BMC_SafetyDataStorage_XIX_SoC_XIX_BMC_HV.SP_IF_BMC_HV_12_BZ_XIX_BMC_SafetyDataStorage_XIX_SoC_XIX_BMC_HV <-> outer port SP_IF_BMC_HV_12_BZ_XIX_BMC_HV
    delegate BMC_SafetyDataStorage_XIX_SoC_XIX_BMC_HV.SP_IF_BMC_HV_12_CRC_XIX_BMC_SafetyDataStorage_XIX_SoC_XIX_BMC_HV <-> outer port SP_IF_BMC_HV_12_CRC_XIX_BMC_HV
    delegate BMC_SafetyDataStorage_XIX_SoC_XIX_BMC_HV.SP_IF_BMC_HV_13_BZ_XIX_BMC_SafetyDataStorage_XIX_SoC_XIX_BMC_HV <-> outer port SP_IF_BMC_HV_13_BZ_XIX_BMC_HV
    delegate BMC_SafetyDataStorage_XIX_SoC_XIX_BMC_HV.SP_IF_BMC_HV_13_CRC_XIX_BMC_SafetyDataStorage_XIX_SoC_XIX_BMC_HV <-> outer port SP_IF_BMC_HV_13_CRC_XIX_BMC_HV
    delegate BMC_SafetyDataStorage_XIX_SoC_XIX_BMC_HV.SP_IF_BMC_Lebensdauer_Trennelemente_XIX_BMC_SafetyDataStorage_XIX_SoC_XIX_BMC_HV <-> outer port SP_IF_BMC_Lebensdauer_Trennelemente_XIX_BMC_HV
    delegate BMC_SafetyDataStorage_XIX_SoC_XIX_BMC_HV.SP_IF_BMC_Sperrung_Ueberspannung_XIX_BMC_SafetyDataStorage_XIX_SoC_XIX_BMC_HV <-> outer port SP_IF_BMC_Sperrung_Ueberspannung_XIX_BMC_HV
    delegate BMC_SafetyDataStorage_XIX_SoC_XIX_BMC_HV.SP_IF_BMC_Sperrung_Uebertemperatur_XIX_BMC_SafetyDataStorage_XIX_SoC_XIX_BMC_HV <-> outer port SP_IF_BMC_Sperrung_Uebertemperatur_XIX_BMC_HV
    delegate BMC_SafetyDataStorage_XIX_SoC_XIX_BMC_HV.SP_IF_BMC_Sperrung_Unterspannung_XIX_BMC_SafetyDataStorage_XIX_SoC_XIX_BMC_HV <-> outer port SP_IF_BMC_Sperrung_Unterspannung_XIX_BMC_HV
    delegate BMC_SafetyDataStorage_XIX_SoC_XIX_BMC_HV.SP_IF_BMC_Status_HV_Spannungssensorik_XIX_BMC_SafetyDataStorage_XIX_SoC_XIX_BMC_HV <-> outer port SP_IF_BMC_Status_HV_Spannungssensorik_XIX_BMC_HV
    delegate BMC_SafetyDataStorage_XIX_SoC_XIX_BMC_HV.SP_IF_BMC_Status_Trennelemente_XIX_BMC_SafetyDataStorage_XIX_SoC_XIX_BMC_HV <-> outer port SP_IF_BMC_Status_Trennelemente_XIX_BMC_HV
    delegate BMC_SafetyDataStorage_XIX_SoC_XIX_BMC_HV.SP_IF_BMC_Ueberspannungszaehler_CMC{01..04}_XIX_BMC_SafetyDataStorage_XIX_SoC_XIX_BMC_HV <-> outer port SP_IF_BMC_Ueberspannungszaehler_CMC{01..04}_XIX_BMC_HV
    delegate BMC_SafetyDataStorage_XIX_SoC_XIX_BMC_HV.SP_IF_BMC_Uebertemperaturzaehler_CMC{01..04}_XIX_BMC_SafetyDataStorage_XIX_SoC_XIX_BMC_HV <-> outer port SP_IF_BMC_Uebertemperaturzaehler_CMC{01..04}_XIX_BMC_HV
    delegate BMC_SafetyDataStorage_XIX_SoC_XIX_BMC_HV.SP_IF_BMC_Unterspannungszaehler_CMC{01..04}_XIX_BMC_SafetyDataStorage_XIX_SoC_XIX_BMC_HV <-> outer port SP_IF_BMC_Unterspannungszaehler_CMC{01..04}_XIX_BMC_HV
    delegate BMC_SafetyDataStorage_XIX_SoC_XIX_BMC_HV.RP_IF_SG_BJB_{10..13}_XIX_BMC_SafetyDataStorage_XIX_SoC_XIX_BMC_HV <-> outer port RP_IF_SG_BJB_{10..13}_XIX_BMC_HV
    delegate HochvoltBatterieManagement_XIX_SoC_XIX_BMC_HV.RP_IF_CHA_ReqPrgBms_XIX_HochvoltBatterieManagement_XIX_SoC_XIX_BMC_HV <-> outer port RP_IF_CHA_ReqPrgBms_XIX_BMC_HV
    delegate HochvoltBatterieManagement_XIX_SoC_XIX_BMC_HV.RP_IF_KST_KL_15_XIX_HochvoltBatterieManagement_XIX_SoC_XIX_BMC_HV <-> outer port RP_IF_KST_KL_15_XIX_BMC_HV
    delegate Infrastructure_Hybrid_01_XIX_network_infrastructure_XIX_BMC_HV.RP_IF_KST_KL_15_XIX_Infrastructure_Hybrid_01_XIX_network_infrastructure_XIX_BMC_HV <-> outer port RP_IF_KST_KL_15_XIX_BMC_HV  # _XIX_ClampControl_XIX_ClampControl_XIX_HCP4_uC1_1_XIX_Infrastructure_Hybrid_01_XIX_network_infrastructure_XIX_BMC_HV_XIX_KST_KL_15
    delegate KS_BMC_HV_XIX_KSGen3_XIX_BMC_HV.RP_IF_SG_KS_Hybrid_01_Challenge_M_XIX_KS_BMC_HV_XIX_KSGen3_XIX_BMC_HV <-> outer port RP_IF_SG_KS_Hybrid_01_Challenge_M_XIX_BMC_HV
    delegate KS_BMC_HV_XIX_KSGen3_XIX_BMC_HV.RP_IF_SG_KS_Hybrid_01_Response_M_XIX_KS_BMC_HV_XIX_KSGen3_XIX_BMC_HV <-> outer port RP_IF_SG_KS_Hybrid_01_Response_M_XIX_BMC_HV
    delegate HochvoltBatterieManagement_XIX_SoC_XIX_BMC_HV.RP_IF_DC_IstLeistung_HV_XIX_HochvoltBatterieManagement_XIX_SoC_XIX_BMC_HV <-> outer port RP_IF_DC_IstLeistung_HV_XIX_BMC_HV
    delegate HVB_Fehlerausgabe_SecondaryOBDECU_XIX_SoC_XIX_BMC_HV.RP_IF_DCDC_NV_Komponentenfehler_72_XIX_HVB_Fehlerausgabe_SecondaryOBDECU_XIX_SoC_XIX_BMC_HV <-> outer port RP_IF_DCDC_NV_Komponentenfehler_72_XIX_BMC_HV  # _XIX_DCDC_SystemControl_XIX_HV_Laden_XIX_DCDC_HV_XIX_HVB_Fehlerausgabe_SecondaryOBDECU_XIX_SoC_XIX_BMC_HV_XIX_DCDC_NV_Komponentenfehler_72
    delegate HVB_Fehlerausgabe_SecondaryOBDECU_XIX_SoC_XIX_BMC_HV.RP_IF_DCDC_NV_Komponentenfehler_3_13_XIX_HVB_Fehlerausgabe_SecondaryOBDECU_XIX_SoC_XIX_BMC_HV <-> outer port RP_IF_DCDC_NV_Komponentenfehler_3_13_XIX_BMC_HV  # _XIX_DCDC_SystemControl_XIX_HV_Laden_XIX_DCDC_HV_XIX_HVB_Fehlerausgabe_SecondaryOBDECU_XIX_SoC_XIX_BMC_HV_XIX_DCDC_NV_Komponentenfehler_3_13
    delegate HVB_Fehlerausgabe_SecondaryOBDECU_XIX_SoC_XIX_BMC_HV.RP_IF_DCDC_NV_Komponentenfehler_40_XIX_HVB_Fehlerausgabe_SecondaryOBDECU_XIX_SoC_XIX_BMC_HV <-> outer port RP_IF_DCDC_NV_Komponentenfehler_40_XIX_BMC_HV  # _XIX_DCDC_SystemControl_XIX_HV_Laden_XIX_DCDC_HV_XIX_HVB_Fehlerausgabe_SecondaryOBDECU_XIX_SoC_XIX_BMC_HV_XIX_DCDC_NV_Komponentenfehler_40
    delegate HVB_Fehlerausgabe_SecondaryOBDECU_XIX_SoC_XIX_BMC_HV.RP_IF_DCDC_NV_Komponentenfehler_VLD_XIX_HVB_Fehlerausgabe_SecondaryOBDECU_XIX_SoC_XIX_BMC_HV <-> outer port RP_IF_DCDC_NV_Komponentenfehler_VLD_XIX_BMC_HV  # _XIX_DCDC_SystemControl_XIX_HV_Laden_XIX_DCDC_HV_XIX_HVB_Fehlerausgabe_SecondaryOBDECU_XIX_SoC_XIX_BMC_HV_XIX_DCDC_NV_Komponentenfehler_VLD
    delegate HVB_Fehlerausgabe_SecondaryOBDECU_XIX_SoC_XIX_BMC_HV.RP_IF_DCDC_NV_Komponentenfehler_34_XIX_HVB_Fehlerausgabe_SecondaryOBDECU_XIX_SoC_XIX_BMC_HV <-> outer port RP_IF_DCDC_NV_Komponentenfehler_34_XIX_BMC_HV  # _XIX_DCDC_SystemControl_XIX_HV_Laden_XIX_DCDC_HV_XIX_HVB_Fehlerausgabe_SecondaryOBDECU_XIX_SoC_XIX_BMC_HV_XIX_DCDC_NV_Komponentenfehler_34
    delegate HVB_Fehlerausgabe_SecondaryOBDECU_XIX_SoC_XIX_BMC_HV.RP_IF_DCDC_NV_Komponentenfehler_65_XIX_HVB_Fehlerausgabe_SecondaryOBDECU_XIX_SoC_XIX_BMC_HV <-> outer port RP_IF_DCDC_NV_Komponentenfehler_65_XIX_BMC_HV  # _XIX_DCDC_SystemControl_XIX_HV_Laden_XIX_DCDC_HV_XIX_HVB_Fehlerausgabe_SecondaryOBDECU_XIX_SoC_XIX_BMC_HV_XIX_DCDC_NV_Komponentenfehler_65
    delegate HVB_Fehlerausgabe_SecondaryOBDECU_XIX_SoC_XIX_BMC_HV.RP_IF_DCDC_NV_Komponentenfehler_73_XIX_HVB_Fehlerausgabe_SecondaryOBDECU_XIX_SoC_XIX_BMC_HV <-> outer port RP_IF_DCDC_NV_Komponentenfehler_73_XIX_BMC_HV  # _XIX_DCDC_SystemControl_XIX_HV_Laden_XIX_DCDC_HV_XIX_HVB_Fehlerausgabe_SecondaryOBDECU_XIX_SoC_XIX_BMC_HV_XIX_DCDC_NV_Komponentenfehler_73
    delegate HVB_Fehlerausgabe_SecondaryOBDECU_XIX_SoC_XIX_BMC_HV.RP_IF_DCDC_NV_Komponentenfehler_3_7_XIX_HVB_Fehlerausgabe_SecondaryOBDECU_XIX_SoC_XIX_BMC_HV <-> outer port RP_IF_DCDC_NV_Komponentenfehler_3_7_XIX_BMC_HV  # _XIX_DCDC_SystemControl_XIX_HV_Laden_XIX_DCDC_HV_XIX_HVB_Fehlerausgabe_SecondaryOBDECU_XIX_SoC_XIX_BMC_HV_XIX_DCDC_NV_Komponentenfehler_3_7
    delegate HVB_Fehlerausgabe_SecondaryOBDECU_XIX_SoC_XIX_BMC_HV.RP_IF_DCDC_NV_Komponentenfehler_36_XIX_HVB_Fehlerausgabe_SecondaryOBDECU_XIX_SoC_XIX_BMC_HV <-> outer port RP_IF_DCDC_NV_Komponentenfehler_36_XIX_BMC_HV  # _XIX_DCDC_SystemControl_XIX_HV_Laden_XIX_DCDC_HV_XIX_HVB_Fehlerausgabe_SecondaryOBDECU_XIX_SoC_XIX_BMC_HV_XIX_DCDC_NV_Komponentenfehler_36
    delegate HVB_Fehlerausgabe_SecondaryOBDECU_XIX_SoC_XIX_BMC_HV.RP_IF_DCDC_NV_Komponentenfehler_3_1_XIX_HVB_Fehlerausgabe_SecondaryOBDECU_XIX_SoC_XIX_BMC_HV <-> outer port RP_IF_DCDC_NV_Komponentenfehler_3_1_XIX_BMC_HV  # _XIX_DCDC_SystemControl_XIX_HV_Laden_XIX_DCDC_HV_XIX_HVB_Fehlerausgabe_SecondaryOBDECU_XIX_SoC_XIX_BMC_HV_XIX_DCDC_NV_Komponentenfehler_3_1
    delegate HVB_Fehlerausgabe_SecondaryOBDECU_XIX_SoC_XIX_BMC_HV.RP_IF_DCDC_NV_Komponentenfehler_3_12_XIX_HVB_Fehlerausgabe_SecondaryOBDECU_XIX_SoC_XIX_BMC_HV <-> outer port RP_IF_DCDC_NV_Komponentenfehler_3_12_XIX_BMC_HV  # _XIX_DCDC_SystemControl_XIX_HV_Laden_XIX_DCDC_HV_XIX_HVB_Fehlerausgabe_SecondaryOBDECU_XIX_SoC_XIX_BMC_HV_XIX_DCDC_NV_Komponentenfehler_3_12
    delegate HVB_Fehlerausgabe_SecondaryOBDECU_XIX_SoC_XIX_BMC_HV.RP_IF_DCDC_NV_Komponentenfehler_22_XIX_HVB_Fehlerausgabe_SecondaryOBDECU_XIX_SoC_XIX_BMC_HV <-> outer port RP_IF_DCDC_NV_Komponentenfehler_22_XIX_BMC_HV  # _XIX_DCDC_SystemControl_XIX_HV_Laden_XIX_DCDC_HV_XIX_HVB_Fehlerausgabe_SecondaryOBDECU_XIX_SoC_XIX_BMC_HV_XIX_DCDC_NV_Komponentenfehler_22
    delegate HVB_Fehlerausgabe_SecondaryOBDECU_XIX_SoC_XIX_BMC_HV.RP_IF_DCDC_NV_Komponentenfehler_32_XIX_HVB_Fehlerausgabe_SecondaryOBDECU_XIX_SoC_XIX_BMC_HV <-> outer port RP_IF_DCDC_NV_Komponentenfehler_32_XIX_BMC_HV  # _XIX_DCDC_SystemControl_XIX_HV_Laden_XIX_DCDC_HV_XIX_HVB_Fehlerausgabe_SecondaryOBDECU_XIX_SoC_XIX_BMC_HV_XIX_DCDC_NV_Komponentenfehler_32
    delegate HVB_Fehlerausgabe_SecondaryOBDECU_XIX_SoC_XIX_BMC_HV.RP_IF_DCDC_NV_Komponentenfehler_47_XIX_HVB_Fehlerausgabe_SecondaryOBDECU_XIX_SoC_XIX_BMC_HV <-> outer port RP_IF_DCDC_NV_Komponentenfehler_47_XIX_BMC_HV  # _XIX_DCDC_SystemControl_XIX_HV_Laden_XIX_DCDC_HV_XIX_HVB_Fehlerausgabe_SecondaryOBDECU_XIX_SoC_XIX_BMC_HV_XIX_DCDC_NV_Komponentenfehler_47
    delegate HVB_Fehlerausgabe_SecondaryOBDECU_XIX_SoC_XIX_BMC_HV.RP_IF_DCDC_NV_Komponentenfehler_3_16_XIX_HVB_Fehlerausgabe_SecondaryOBDECU_XIX_SoC_XIX_BMC_HV <-> outer port RP_IF_DCDC_NV_Komponentenfehler_3_16_XIX_BMC_HV  # _XIX_DCDC_SystemControl_XIX_HV_Laden_XIX_DCDC_HV_XIX_HVB_Fehlerausgabe_SecondaryOBDECU_XIX_SoC_XIX_BMC_HV_XIX_DCDC_NV_Komponentenfehler_3_16
    delegate HVB_Fehlerausgabe_SecondaryOBDECU_XIX_SoC_XIX_BMC_HV.RP_IF_DCDC_NV_Komponentenfehler_38_XIX_HVB_Fehlerausgabe_SecondaryOBDECU_XIX_SoC_XIX_BMC_HV <-> outer port RP_IF_DCDC_NV_Komponentenfehler_38_XIX_BMC_HV  # _XIX_DCDC_SystemControl_XIX_HV_Laden_XIX_DCDC_HV_XIX_HVB_Fehlerausgabe_SecondaryOBDECU_XIX_SoC_XIX_BMC_HV_XIX_DCDC_NV_Komponentenfehler_38
    delegate HVB_Fehlerausgabe_SecondaryOBDECU_XIX_SoC_XIX_BMC_HV.RP_IF_DCDC_NV_Komponentenfehler_3_10_XIX_HVB_Fehlerausgabe_SecondaryOBDECU_XIX_SoC_XIX_BMC_HV <-> outer port RP_IF_DCDC_NV_Komponentenfehler_3_10_XIX_BMC_HV  # _XIX_DCDC_SystemControl_XIX_HV_Laden_XIX_DCDC_HV_XIX_HVB_Fehlerausgabe_SecondaryOBDECU_XIX_SoC_XIX_BMC_HV_XIX_DCDC_NV_Komponentenfehler_3_10
    delegate HVB_Fehlerausgabe_SecondaryOBDECU_XIX_SoC_XIX_BMC_HV.RP_IF_DCDC_NV_Komponentenfehler_55_XIX_HVB_Fehlerausgabe_SecondaryOBDECU_XIX_SoC_XIX_BMC_HV <-> outer port RP_IF_DCDC_NV_Komponentenfehler_55_XIX_BMC_HV  # _XIX_DCDC_SystemControl_XIX_HV_Laden_XIX_DCDC_HV_XIX_HVB_Fehlerausgabe_SecondaryOBDECU_XIX_SoC_XIX_BMC_HV_XIX_DCDC_NV_Komponentenfehler_55
    delegate HVB_Fehlerausgabe_SecondaryOBDECU_XIX_SoC_XIX_BMC_HV.RP_IF_DCDC_NV_Komponentenfehler_76_XIX_HVB_Fehlerausgabe_SecondaryOBDECU_XIX_SoC_XIX_BMC_HV <-> outer port RP_IF_DCDC_NV_Komponentenfehler_76_XIX_BMC_HV  # _XIX_DCDC_SystemControl_XIX_HV_Laden_XIX_DCDC_HV_XIX_HVB_Fehlerausgabe_SecondaryOBDECU_XIX_SoC_XIX_BMC_HV_XIX_DCDC_NV_Komponentenfehler_76
    delegate HVB_Fehlerausgabe_SecondaryOBDECU_XIX_SoC_XIX_BMC_HV.RP_IF_DCDC_NV_Komponentenfehler_43_XIX_HVB_Fehlerausgabe_SecondaryOBDECU_XIX_SoC_XIX_BMC_HV <-> outer port RP_IF_DCDC_NV_Komponentenfehler_43_XIX_BMC_HV  # _XIX_DCDC_SystemControl_XIX_HV_Laden_XIX_DCDC_HV_XIX_HVB_Fehlerausgabe_SecondaryOBDECU_XIX_SoC_XIX_BMC_HV_XIX_DCDC_NV_Komponentenfehler_43
    delegate HVB_Fehlerausgabe_SecondaryOBDECU_XIX_SoC_XIX_BMC_HV.RP_IF_DCDC_NV_Komponentenfehler_26_XIX_HVB_Fehlerausgabe_SecondaryOBDECU_XIX_SoC_XIX_BMC_HV <-> outer port RP_IF_DCDC_NV_Komponentenfehler_26_XIX_BMC_HV  # _XIX_DCDC_SystemControl_XIX_HV_Laden_XIX_DCDC_HV_XIX_HVB_Fehlerausgabe_SecondaryOBDECU_XIX_SoC_XIX_BMC_HV_XIX_DCDC_NV_Komponentenfehler_26
    delegate HVB_Fehlerausgabe_SecondaryOBDECU_XIX_SoC_XIX_BMC_HV.RP_IF_DCDC_NV_Komponentenfehler_05_XIX_HVB_Fehlerausgabe_SecondaryOBDECU_XIX_SoC_XIX_BMC_HV <-> outer port RP_IF_DCDC_NV_Komponentenfehler_05_XIX_BMC_HV  # _XIX_DCDC_SystemControl_XIX_HV_Laden_XIX_DCDC_HV_XIX_HVB_Fehlerausgabe_SecondaryOBDECU_XIX_SoC_XIX_BMC_HV_XIX_DCDC_NV_Komponentenfehler_05
    delegate HVB_Fehlerausgabe_SecondaryOBDECU_XIX_SoC_XIX_BMC_HV.RP_IF_DCDC_NV_Komponentenfehler_56_XIX_HVB_Fehlerausgabe_SecondaryOBDECU_XIX_SoC_XIX_BMC_HV <-> outer port RP_IF_DCDC_NV_Komponentenfehler_56_XIX_BMC_HV  # _XIX_DCDC_SystemControl_XIX_HV_Laden_XIX_DCDC_HV_XIX_HVB_Fehlerausgabe_SecondaryOBDECU_XIX_SoC_XIX_BMC_HV_XIX_DCDC_NV_Komponentenfehler_56
    delegate HVB_Fehlerausgabe_SecondaryOBDECU_XIX_SoC_XIX_BMC_HV.RP_IF_DCDC_NV_Komponentenfehler_11_XIX_HVB_Fehlerausgabe_SecondaryOBDECU_XIX_SoC_XIX_BMC_HV <-> outer port RP_IF_DCDC_NV_Komponentenfehler_11_XIX_BMC_HV  # _XIX_DCDC_SystemControl_XIX_HV_Laden_XIX_DCDC_HV_XIX_HVB_Fehlerausgabe_SecondaryOBDECU_XIX_SoC_XIX_BMC_HV_XIX_DCDC_NV_Komponentenfehler_11
    delegate HVB_Fehlerausgabe_SecondaryOBDECU_XIX_SoC_XIX_BMC_HV.RP_IF_DCDC_NV_Komponentenfehler_14_XIX_HVB_Fehlerausgabe_SecondaryOBDECU_XIX_SoC_XIX_BMC_HV <-> outer port RP_IF_DCDC_NV_Komponentenfehler_14_XIX_BMC_HV  # _XIX_DCDC_SystemControl_XIX_HV_Laden_XIX_DCDC_HV_XIX_HVB_Fehlerausgabe_SecondaryOBDECU_XIX_SoC_XIX_BMC_HV_XIX_DCDC_NV_Komponentenfehler_14
    delegate HVB_Fehlerausgabe_SecondaryOBDECU_XIX_SoC_XIX_BMC_HV.RP_IF_DCDC_NV_Komponentenfehler_77_XIX_HVB_Fehlerausgabe_SecondaryOBDECU_XIX_SoC_XIX_BMC_HV <-> outer port RP_IF_DCDC_NV_Komponentenfehler_77_XIX_BMC_HV  # _XIX_DCDC_SystemControl_XIX_HV_Laden_XIX_DCDC_HV_XIX_HVB_Fehlerausgabe_SecondaryOBDECU_XIX_SoC_XIX_BMC_HV_XIX_DCDC_NV_Komponentenfehler_77
    delegate HVB_Fehlerausgabe_SecondaryOBDECU_XIX_SoC_XIX_BMC_HV.RP_IF_DCDC_NV_Komponentenfehler_18_XIX_HVB_Fehlerausgabe_SecondaryOBDECU_XIX_SoC_XIX_BMC_HV <-> outer port RP_IF_DCDC_NV_Komponentenfehler_18_XIX_BMC_HV  # _XIX_DCDC_SystemControl_XIX_HV_Laden_XIX_DCDC_HV_XIX_HVB_Fehlerausgabe_SecondaryOBDECU_XIX_SoC_XIX_BMC_HV_XIX_DCDC_NV_Komponentenfehler_18
    delegate HVB_Fehlerausgabe_SecondaryOBDECU_XIX_SoC_XIX_BMC_HV.RP_IF_DCDC_NV_Komponentenfehler_59_XIX_HVB_Fehlerausgabe_SecondaryOBDECU_XIX_SoC_XIX_BMC_HV <-> outer port RP_IF_DCDC_NV_Komponentenfehler_59_XIX_BMC_HV  # _XIX_DCDC_SystemControl_XIX_HV_Laden_XIX_DCDC_HV_XIX_HVB_Fehlerausgabe_SecondaryOBDECU_XIX_SoC_XIX_BMC_HV_XIX_DCDC_NV_Komponentenfehler_59
    delegate HVB_Fehlerausgabe_SecondaryOBDECU_XIX_SoC_XIX_BMC_HV.RP_IF_DCDC_NV_Komponentenfehler_45_XIX_HVB_Fehlerausgabe_SecondaryOBDECU_XIX_SoC_XIX_BMC_HV <-> outer port RP_IF_DCDC_NV_Komponentenfehler_45_XIX_BMC_HV  # _XIX_DCDC_SystemControl_XIX_HV_Laden_XIX_DCDC_HV_XIX_HVB_Fehlerausgabe_SecondaryOBDECU_XIX_SoC_XIX_BMC_HV_XIX_DCDC_NV_Komponentenfehler_45
    delegate HVB_Fehlerausgabe_SecondaryOBDECU_XIX_SoC_XIX_BMC_HV.RP_IF_DCDC_NV_Komponentenfehler_30_XIX_HVB_Fehlerausgabe_SecondaryOBDECU_XIX_SoC_XIX_BMC_HV <-> outer port RP_IF_DCDC_NV_Komponentenfehler_30_XIX_BMC_HV  # _XIX_DCDC_SystemControl_XIX_HV_Laden_XIX_DCDC_HV_XIX_HVB_Fehlerausgabe_SecondaryOBDECU_XIX_SoC_XIX_BMC_HV_XIX_DCDC_NV_Komponentenfehler_30
    delegate HVB_Fehlerausgabe_SecondaryOBDECU_XIX_SoC_XIX_BMC_HV.RP_IF_DCDC_NV_Komponentenfehler_04_XIX_HVB_Fehlerausgabe_SecondaryOBDECU_XIX_SoC_XIX_BMC_HV <-> outer port RP_IF_DCDC_NV_Komponentenfehler_04_XIX_BMC_HV  # _XIX_DCDC_SystemControl_XIX_HV_Laden_XIX_DCDC_HV_XIX_HVB_Fehlerausgabe_SecondaryOBDECU_XIX_SoC_XIX_BMC_HV_XIX_DCDC_NV_Komponentenfehler_04
    delegate HVB_Fehlerausgabe_SecondaryOBDECU_XIX_SoC_XIX_BMC_HV.RP_IF_DCDC_NV_Komponentenfehler_09_XIX_HVB_Fehlerausgabe_SecondaryOBDECU_XIX_SoC_XIX_BMC_HV <-> outer port RP_IF_DCDC_NV_Komponentenfehler_09_XIX_BMC_HV  # _XIX_DCDC_SystemControl_XIX_HV_Laden_XIX_DCDC_HV_XIX_HVB_Fehlerausgabe_SecondaryOBDECU_XIX_SoC_XIX_BMC_HV_XIX_DCDC_NV_Komponentenfehler_09
    delegate HVB_Fehlerausgabe_SecondaryOBDECU_XIX_SoC_XIX_BMC_HV.RP_IF_DCDC_NV_Komponentenfehler_3_8_XIX_HVB_Fehlerausgabe_SecondaryOBDECU_XIX_SoC_XIX_BMC_HV <-> outer port RP_IF_DCDC_NV_Komponentenfehler_3_8_XIX_BMC_HV  # _XIX_DCDC_SystemControl_XIX_HV_Laden_XIX_DCDC_HV_XIX_HVB_Fehlerausgabe_SecondaryOBDECU_XIX_SoC_XIX_BMC_HV_XIX_DCDC_NV_Komponentenfehler_3_8
    delegate HVB_Fehlerausgabe_SecondaryOBDECU_XIX_SoC_XIX_BMC_HV.RP_IF_DCDC_NV_Komponentenfehler_02_XIX_HVB_Fehlerausgabe_SecondaryOBDECU_XIX_SoC_XIX_BMC_HV <-> outer port RP_IF_DCDC_NV_Komponentenfehler_02_XIX_BMC_HV  # _XIX_DCDC_SystemControl_XIX_HV_Laden_XIX_DCDC_HV_XIX_HVB_Fehlerausgabe_SecondaryOBDECU_XIX_SoC_XIX_BMC_HV_XIX_DCDC_NV_Komponentenfehler_02
    delegate HVB_Fehlerausgabe_SecondaryOBDECU_XIX_SoC_XIX_BMC_HV.RP_IF_DCDC_NV_Komponentenfehler_54_XIX_HVB_Fehlerausgabe_SecondaryOBDECU_XIX_SoC_XIX_BMC_HV <-> outer port RP_IF_DCDC_NV_Komponentenfehler_54_XIX_BMC_HV  # _XIX_DCDC_SystemControl_XIX_HV_Laden_XIX_DCDC_HV_XIX_HVB_Fehlerausgabe_SecondaryOBDECU_XIX_SoC_XIX_BMC_HV_XIX_DCDC_NV_Komponentenfehler_54
    delegate HVB_Fehlerausgabe_SecondaryOBDECU_XIX_SoC_XIX_BMC_HV.RP_IF_DCDC_NV_Komponentenfehler_53_XIX_HVB_Fehlerausgabe_SecondaryOBDECU_XIX_SoC_XIX_BMC_HV <-> outer port RP_IF_DCDC_NV_Komponentenfehler_53_XIX_BMC_HV  # _XIX_DCDC_SystemControl_XIX_HV_Laden_XIX_DCDC_HV_XIX_HVB_Fehlerausgabe_SecondaryOBDECU_XIX_SoC_XIX_BMC_HV_XIX_DCDC_NV_Komponentenfehler_53
    delegate HVB_Fehlerausgabe_SecondaryOBDECU_XIX_SoC_XIX_BMC_HV.RP_IF_DCDC_NV_Komponentenfehler_66_XIX_HVB_Fehlerausgabe_SecondaryOBDECU_XIX_SoC_XIX_BMC_HV <-> outer port RP_IF_DCDC_NV_Komponentenfehler_66_XIX_BMC_HV  # _XIX_DCDC_SystemControl_XIX_HV_Laden_XIX_DCDC_HV_XIX_HVB_Fehlerausgabe_SecondaryOBDECU_XIX_SoC_XIX_BMC_HV_XIX_DCDC_NV_Komponentenfehler_66
    delegate HVB_Fehlerausgabe_SecondaryOBDECU_XIX_SoC_XIX_BMC_HV.RP_IF_DCDC_NV_Komponentenfehler_68_XIX_HVB_Fehlerausgabe_SecondaryOBDECU_XIX_SoC_XIX_BMC_HV <-> outer port RP_IF_DCDC_NV_Komponentenfehler_68_XIX_BMC_HV  # _XIX_DCDC_SystemControl_XIX_HV_Laden_XIX_DCDC_HV_XIX_HVB_Fehlerausgabe_SecondaryOBDECU_XIX_SoC_XIX_BMC_HV_XIX_DCDC_NV_Komponentenfehler_68
    delegate HVB_Fehlerausgabe_SecondaryOBDECU_XIX_SoC_XIX_BMC_HV.RP_IF_DCDC_NV_Komponentenfehler_51_XIX_HVB_Fehlerausgabe_SecondaryOBDECU_XIX_SoC_XIX_BMC_HV <-> outer port RP_IF_DCDC_NV_Komponentenfehler_51_XIX_BMC_HV  # _XIX_DCDC_SystemControl_XIX_HV_Laden_XIX_DCDC_HV_XIX_HVB_Fehlerausgabe_SecondaryOBDECU_XIX_SoC_XIX_BMC_HV_XIX_DCDC_NV_Komponentenfehler_51
    delegate HVB_Fehlerausgabe_SecondaryOBDECU_XIX_SoC_XIX_BMC_HV.RP_IF_DCDC_NV_Komponentenfehler_35_XIX_HVB_Fehlerausgabe_SecondaryOBDECU_XIX_SoC_XIX_BMC_HV <-> outer port RP_IF_DCDC_NV_Komponentenfehler_35_XIX_BMC_HV  # _XIX_DCDC_SystemControl_XIX_HV_Laden_XIX_DCDC_HV_XIX_HVB_Fehlerausgabe_SecondaryOBDECU_XIX_SoC_XIX_BMC_HV_XIX_DCDC_NV_Komponentenfehler_35
    delegate HVB_Fehlerausgabe_SecondaryOBDECU_XIX_SoC_XIX_BMC_HV.RP_IF_DCDC_NV_Komponentenfehler_31_XIX_HVB_Fehlerausgabe_SecondaryOBDECU_XIX_SoC_XIX_BMC_HV <-> outer port RP_IF_DCDC_NV_Komponentenfehler_31_XIX_BMC_HV  # _XIX_DCDC_SystemControl_XIX_HV_Laden_XIX_DCDC_HV_XIX_HVB_Fehlerausgabe_SecondaryOBDECU_XIX_SoC_XIX_BMC_HV_XIX_DCDC_NV_Komponentenfehler_31
    delegate HVB_Fehlerausgabe_SecondaryOBDECU_XIX_SoC_XIX_BMC_HV.RP_IF_DCDC_NV_Komponentenfehler_48_XIX_HVB_Fehlerausgabe_SecondaryOBDECU_XIX_SoC_XIX_BMC_HV <-> outer port RP_IF_DCDC_NV_Komponentenfehler_48_XIX_BMC_HV  # _XIX_DCDC_SystemControl_XIX_HV_Laden_XIX_DCDC_HV_XIX_HVB_Fehlerausgabe_SecondaryOBDECU_XIX_SoC_XIX_BMC_HV_XIX_DCDC_NV_Komponentenfehler_48
    delegate HVB_Fehlerausgabe_SecondaryOBDECU_XIX_SoC_XIX_BMC_HV.RP_IF_DCDC_NV_Komponentenfehler_07_XIX_HVB_Fehlerausgabe_SecondaryOBDECU_XIX_SoC_XIX_BMC_HV <-> outer port RP_IF_DCDC_NV_Komponentenfehler_07_XIX_BMC_HV  # _XIX_DCDC_SystemControl_XIX_HV_Laden_XIX_DCDC_HV_XIX_HVB_Fehlerausgabe_SecondaryOBDECU_XIX_SoC_XIX_BMC_HV_XIX_DCDC_NV_Komponentenfehler_07
    delegate HVB_Fehlerausgabe_SecondaryOBDECU_XIX_SoC_XIX_BMC_HV.RP_IF_DCDC_NV_Komponentenfehler_67_XIX_HVB_Fehlerausgabe_SecondaryOBDECU_XIX_SoC_XIX_BMC_HV <-> outer port RP_IF_DCDC_NV_Komponentenfehler_67_XIX_BMC_HV  # _XIX_DCDC_SystemControl_XIX_HV_Laden_XIX_DCDC_HV_XIX_HVB_Fehlerausgabe_SecondaryOBDECU_XIX_SoC_XIX_BMC_HV_XIX_DCDC_NV_Komponentenfehler_67
    delegate HVB_Fehlerausgabe_SecondaryOBDECU_XIX_SoC_XIX_BMC_HV.RP_IF_DCDC_NV_Komponentenfehler_08_XIX_HVB_Fehlerausgabe_SecondaryOBDECU_XIX_SoC_XIX_BMC_HV <-> outer port RP_IF_DCDC_NV_Komponentenfehler_08_XIX_BMC_HV  # _XIX_DCDC_SystemControl_XIX_HV_Laden_XIX_DCDC_HV_XIX_HVB_Fehlerausgabe_SecondaryOBDECU_XIX_SoC_XIX_BMC_HV_XIX_DCDC_NV_Komponentenfehler_08
    delegate HVB_Fehlerausgabe_SecondaryOBDECU_XIX_SoC_XIX_BMC_HV.RP_IF_DCDC_NV_Komponentenfehler_27_XIX_HVB_Fehlerausgabe_SecondaryOBDECU_XIX_SoC_XIX_BMC_HV <-> outer port RP_IF_DCDC_NV_Komponentenfehler_27_XIX_BMC_HV  # _XIX_DCDC_SystemControl_XIX_HV_Laden_XIX_DCDC_HV_XIX_HVB_Fehlerausgabe_SecondaryOBDECU_XIX_SoC_XIX_BMC_HV_XIX_DCDC_NV_Komponentenfehler_27
    delegate HVB_Fehlerausgabe_SecondaryOBDECU_XIX_SoC_XIX_BMC_HV.RP_IF_DCDC_NV_Komponentenfehler_69_XIX_HVB_Fehlerausgabe_SecondaryOBDECU_XIX_SoC_XIX_BMC_HV <-> outer port RP_IF_DCDC_NV_Komponentenfehler_69_XIX_BMC_HV  # _XIX_DCDC_SystemControl_XIX_HV_Laden_XIX_DCDC_HV_XIX_HVB_Fehlerausgabe_SecondaryOBDECU_XIX_SoC_XIX_BMC_HV_XIX_DCDC_NV_Komponentenfehler_69
    delegate HVB_Fehlerausgabe_SecondaryOBDECU_XIX_SoC_XIX_BMC_HV.RP_IF_DCDC_NV_Komponentenfehler_13_XIX_HVB_Fehlerausgabe_SecondaryOBDECU_XIX_SoC_XIX_BMC_HV <-> outer port RP_IF_DCDC_NV_Komponentenfehler_13_XIX_BMC_HV  # _XIX_DCDC_SystemControl_XIX_HV_Laden_XIX_DCDC_HV_XIX_HVB_Fehlerausgabe_SecondaryOBDECU_XIX_SoC_XIX_BMC_HV_XIX_DCDC_NV_Komponentenfehler_13
    delegate HVB_Fehlerausgabe_SecondaryOBDECU_XIX_SoC_XIX_BMC_HV.RP_IF_DCDC_NV_Komponentenfehler_20_XIX_HVB_Fehlerausgabe_SecondaryOBDECU_XIX_SoC_XIX_BMC_HV <-> outer port RP_IF_DCDC_NV_Komponentenfehler_20_XIX_BMC_HV  # _XIX_DCDC_SystemControl_XIX_HV_Laden_XIX_DCDC_HV_XIX_HVB_Fehlerausgabe_SecondaryOBDECU_XIX_SoC_XIX_BMC_HV_XIX_DCDC_NV_Komponentenfehler_20
    delegate HVB_Fehlerausgabe_SecondaryOBDECU_XIX_SoC_XIX_BMC_HV.RP_IF_DCDC_NV_Komponentenfehler_15_XIX_HVB_Fehlerausgabe_SecondaryOBDECU_XIX_SoC_XIX_BMC_HV <-> outer port RP_IF_DCDC_NV_Komponentenfehler_15_XIX_BMC_HV  # _XIX_DCDC_SystemControl_XIX_HV_Laden_XIX_DCDC_HV_XIX_HVB_Fehlerausgabe_SecondaryOBDECU_XIX_SoC_XIX_BMC_HV_XIX_DCDC_NV_Komponentenfehler_15
    delegate HVB_Fehlerausgabe_SecondaryOBDECU_XIX_SoC_XIX_BMC_HV.RP_IF_DCDC_NV_Komponentenfehler_44_XIX_HVB_Fehlerausgabe_SecondaryOBDECU_XIX_SoC_XIX_BMC_HV <-> outer port RP_IF_DCDC_NV_Komponentenfehler_44_XIX_BMC_HV  # _XIX_DCDC_SystemControl_XIX_HV_Laden_XIX_DCDC_HV_XIX_HVB_Fehlerausgabe_SecondaryOBDECU_XIX_SoC_XIX_BMC_HV_XIX_DCDC_NV_Komponentenfehler_44
    delegate HVB_Fehlerausgabe_SecondaryOBDECU_XIX_SoC_XIX_BMC_HV.RP_IF_DCDC_NV_Komponentenfehler_03_XIX_HVB_Fehlerausgabe_SecondaryOBDECU_XIX_SoC_XIX_BMC_HV <-> outer port RP_IF_DCDC_NV_Komponentenfehler_03_XIX_BMC_HV  # _XIX_DCDC_SystemControl_XIX_HV_Laden_XIX_DCDC_HV_XIX_HVB_Fehlerausgabe_SecondaryOBDECU_XIX_SoC_XIX_BMC_HV_XIX_DCDC_NV_Komponentenfehler_03
    delegate HVB_Fehlerausgabe_SecondaryOBDECU_XIX_SoC_XIX_BMC_HV.RP_IF_DCDC_NV_Komponentenfehler_3_5_XIX_HVB_Fehlerausgabe_SecondaryOBDECU_XIX_SoC_XIX_BMC_HV <-> outer port RP_IF_DCDC_NV_Komponentenfehler_3_5_XIX_BMC_HV  # _XIX_DCDC_SystemControl_XIX_HV_Laden_XIX_DCDC_HV_XIX_HVB_Fehlerausgabe_SecondaryOBDECU_XIX_SoC_XIX_BMC_HV_XIX_DCDC_NV_Komponentenfehler_3_5
    delegate HVB_Fehlerausgabe_SecondaryOBDECU_XIX_SoC_XIX_BMC_HV.RP_IF_DCDC_NV_Komponentenfehler_79_XIX_HVB_Fehlerausgabe_SecondaryOBDECU_XIX_SoC_XIX_BMC_HV <-> outer port RP_IF_DCDC_NV_Komponentenfehler_79_XIX_BMC_HV  # _XIX_DCDC_SystemControl_XIX_HV_Laden_XIX_DCDC_HV_XIX_HVB_Fehlerausgabe_SecondaryOBDECU_XIX_SoC_XIX_BMC_HV_XIX_DCDC_NV_Komponentenfehler_79
    delegate HVB_Fehlerausgabe_SecondaryOBDECU_XIX_SoC_XIX_BMC_HV.RP_IF_DCDC_NV_Komponentenfehler_52_XIX_HVB_Fehlerausgabe_SecondaryOBDECU_XIX_SoC_XIX_BMC_HV <-> outer port RP_IF_DCDC_NV_Komponentenfehler_52_XIX_BMC_HV  # _XIX_DCDC_SystemControl_XIX_HV_Laden_XIX_DCDC_HV_XIX_HVB_Fehlerausgabe_SecondaryOBDECU_XIX_SoC_XIX_BMC_HV_XIX_DCDC_NV_Komponentenfehler_52
    delegate HVB_Fehlerausgabe_SecondaryOBDECU_XIX_SoC_XIX_BMC_HV.RP_IF_DCDC_NV_Komponentenfehler_3_14_XIX_HVB_Fehlerausgabe_SecondaryOBDECU_XIX_SoC_XIX_BMC_HV <-> outer port RP_IF_DCDC_NV_Komponentenfehler_3_14_XIX_BMC_HV  # _XIX_DCDC_SystemControl_XIX_HV_Laden_XIX_DCDC_HV_XIX_HVB_Fehlerausgabe_SecondaryOBDECU_XIX_SoC_XIX_BMC_HV_XIX_DCDC_NV_Komponentenfehler_3_14
    delegate HVB_Fehlerausgabe_SecondaryOBDECU_XIX_SoC_XIX_BMC_HV.RP_IF_DCDC_NV_Komponentenfehler_3_3_XIX_HVB_Fehlerausgabe_SecondaryOBDECU_XIX_SoC_XIX_BMC_HV <-> outer port RP_IF_DCDC_NV_Komponentenfehler_3_3_XIX_BMC_HV  # _XIX_DCDC_SystemControl_XIX_HV_Laden_XIX_DCDC_HV_XIX_HVB_Fehlerausgabe_SecondaryOBDECU_XIX_SoC_XIX_BMC_HV_XIX_DCDC_NV_Komponentenfehler_3_3
    delegate HVB_Fehlerausgabe_SecondaryOBDECU_XIX_SoC_XIX_BMC_HV.RP_IF_DCDC_NV_Komponentenfehler_58_XIX_HVB_Fehlerausgabe_SecondaryOBDECU_XIX_SoC_XIX_BMC_HV <-> outer port RP_IF_DCDC_NV_Komponentenfehler_58_XIX_BMC_HV  # _XIX_DCDC_SystemControl_XIX_HV_Laden_XIX_DCDC_HV_XIX_HVB_Fehlerausgabe_SecondaryOBDECU_XIX_SoC_XIX_BMC_HV_XIX_DCDC_NV_Komponentenfehler_58
    delegate HVB_Fehlerausgabe_SecondaryOBDECU_XIX_SoC_XIX_BMC_HV.RP_IF_DCDC_NV_Komponentenfehler_25_XIX_HVB_Fehlerausgabe_SecondaryOBDECU_XIX_SoC_XIX_BMC_HV <-> outer port RP_IF_DCDC_NV_Komponentenfehler_25_XIX_BMC_HV  # _XIX_DCDC_SystemControl_XIX_HV_Laden_XIX_DCDC_HV_XIX_HVB_Fehlerausgabe_SecondaryOBDECU_XIX_SoC_XIX_BMC_HV_XIX_DCDC_NV_Komponentenfehler_25
    delegate HVB_Fehlerausgabe_SecondaryOBDECU_XIX_SoC_XIX_BMC_HV.RP_IF_DCDC_NV_Komponentenfehler_33_XIX_HVB_Fehlerausgabe_SecondaryOBDECU_XIX_SoC_XIX_BMC_HV <-> outer port RP_IF_DCDC_NV_Komponentenfehler_33_XIX_BMC_HV  # _XIX_DCDC_SystemControl_XIX_HV_Laden_XIX_DCDC_HV_XIX_HVB_Fehlerausgabe_SecondaryOBDECU_XIX_SoC_XIX_BMC_HV_XIX_DCDC_NV_Komponentenfehler_33
    delegate HVB_Fehlerausgabe_SecondaryOBDECU_XIX_SoC_XIX_BMC_HV.RP_IF_DCDC_NV_Komponentenfehler_16_XIX_HVB_Fehlerausgabe_SecondaryOBDECU_XIX_SoC_XIX_BMC_HV <-> outer port RP_IF_DCDC_NV_Komponentenfehler_16_XIX_BMC_HV  # _XIX_DCDC_SystemControl_XIX_HV_Laden_XIX_DCDC_HV_XIX_HVB_Fehlerausgabe_SecondaryOBDECU_XIX_SoC_XIX_BMC_HV_XIX_DCDC_NV_Komponentenfehler_16
    delegate HVB_Fehlerausgabe_SecondaryOBDECU_XIX_SoC_XIX_BMC_HV.RP_IF_DCDC_NV_Komponentenfehler_74_XIX_HVB_Fehlerausgabe_SecondaryOBDECU_XIX_SoC_XIX_BMC_HV <-> outer port RP_IF_DCDC_NV_Komponentenfehler_74_XIX_BMC_HV  # _XIX_DCDC_SystemControl_XIX_HV_Laden_XIX_DCDC_HV_XIX_HVB_Fehlerausgabe_SecondaryOBDECU_XIX_SoC_XIX_BMC_HV_XIX_DCDC_NV_Komponentenfehler_74
    delegate HVB_Fehlerausgabe_SecondaryOBDECU_XIX_SoC_XIX_BMC_HV.RP_IF_DCDC_NV_Komponentenfehler_46_XIX_HVB_Fehlerausgabe_SecondaryOBDECU_XIX_SoC_XIX_BMC_HV <-> outer port RP_IF_DCDC_NV_Komponentenfehler_46_XIX_BMC_HV  # _XIX_DCDC_SystemControl_XIX_HV_Laden_XIX_DCDC_HV_XIX_HVB_Fehlerausgabe_SecondaryOBDECU_XIX_SoC_XIX_BMC_HV_XIX_DCDC_NV_Komponentenfehler_46
    delegate HVB_Fehlerausgabe_SecondaryOBDECU_XIX_SoC_XIX_BMC_HV.RP_IF_DCDC_NV_Komponentenfehler_50_XIX_HVB_Fehlerausgabe_SecondaryOBDECU_XIX_SoC_XIX_BMC_HV <-> outer port RP_IF_DCDC_NV_Komponentenfehler_50_XIX_BMC_HV  # _XIX_DCDC_SystemControl_XIX_HV_Laden_XIX_DCDC_HV_XIX_HVB_Fehlerausgabe_SecondaryOBDECU_XIX_SoC_XIX_BMC_HV_XIX_DCDC_NV_Komponentenfehler_50
    delegate HVB_Fehlerausgabe_SecondaryOBDECU_XIX_SoC_XIX_BMC_HV.RP_IF_DCDC_NV_Komponentenfehler_3_6_XIX_HVB_Fehlerausgabe_SecondaryOBDECU_XIX_SoC_XIX_BMC_HV <-> outer port RP_IF_DCDC_NV_Komponentenfehler_3_6_XIX_BMC_HV  # _XIX_DCDC_SystemControl_XIX_HV_Laden_XIX_DCDC_HV_XIX_HVB_Fehlerausgabe_SecondaryOBDECU_XIX_SoC_XIX_BMC_HV_XIX_DCDC_NV_Komponentenfehler_3_6
    delegate HVB_Fehlerausgabe_SecondaryOBDECU_XIX_SoC_XIX_BMC_HV.RP_IF_DCDC_NV_Komponentenfehler_3_2_XIX_HVB_Fehlerausgabe_SecondaryOBDECU_XIX_SoC_XIX_BMC_HV <-> outer port RP_IF_DCDC_NV_Komponentenfehler_3_2_XIX_BMC_HV  # _XIX_DCDC_SystemControl_XIX_HV_Laden_XIX_DCDC_HV_XIX_HVB_Fehlerausgabe_SecondaryOBDECU_XIX_SoC_XIX_BMC_HV_XIX_DCDC_NV_Komponentenfehler_3_2
    delegate HVB_Fehlerausgabe_SecondaryOBDECU_XIX_SoC_XIX_BMC_HV.RP_IF_DCDC_NV_Komponentenfehler_70_XIX_HVB_Fehlerausgabe_SecondaryOBDECU_XIX_SoC_XIX_BMC_HV <-> outer port RP_IF_DCDC_NV_Komponentenfehler_70_XIX_BMC_HV  # _XIX_DCDC_SystemControl_XIX_HV_Laden_XIX_DCDC_HV_XIX_HVB_Fehlerausgabe_SecondaryOBDECU_XIX_SoC_XIX_BMC_HV_XIX_DCDC_NV_Komponentenfehler_70
    delegate HVB_Fehlerausgabe_SecondaryOBDECU_XIX_SoC_XIX_BMC_HV.RP_IF_DCDC_NV_Komponentenfehler_17_XIX_HVB_Fehlerausgabe_SecondaryOBDECU_XIX_SoC_XIX_BMC_HV <-> outer port RP_IF_DCDC_NV_Komponentenfehler_17_XIX_BMC_HV  # _XIX_DCDC_SystemControl_XIX_HV_Laden_XIX_DCDC_HV_XIX_HVB_Fehlerausgabe_SecondaryOBDECU_XIX_SoC_XIX_BMC_HV_XIX_DCDC_NV_Komponentenfehler_17
    delegate HVB_Fehlerausgabe_SecondaryOBDECU_XIX_SoC_XIX_BMC_HV.RP_IF_DCDC_NV_Komponentenfehler_3_15_XIX_HVB_Fehlerausgabe_SecondaryOBDECU_XIX_SoC_XIX_BMC_HV <-> outer port RP_IF_DCDC_NV_Komponentenfehler_3_15_XIX_BMC_HV  # _XIX_DCDC_SystemControl_XIX_HV_Laden_XIX_DCDC_HV_XIX_HVB_Fehlerausgabe_SecondaryOBDECU_XIX_SoC_XIX_BMC_HV_XIX_DCDC_NV_Komponentenfehler_3_15
    delegate HVB_Fehlerausgabe_SecondaryOBDECU_XIX_SoC_XIX_BMC_HV.RP_IF_DCDC_NV_Komponentenfehler_06_XIX_HVB_Fehlerausgabe_SecondaryOBDECU_XIX_SoC_XIX_BMC_HV <-> outer port RP_IF_DCDC_NV_Komponentenfehler_06_XIX_BMC_HV  # _XIX_DCDC_SystemControl_XIX_HV_Laden_XIX_DCDC_HV_XIX_HVB_Fehlerausgabe_SecondaryOBDECU_XIX_SoC_XIX_BMC_HV_XIX_DCDC_NV_Komponentenfehler_06
    delegate HVB_Fehlerausgabe_SecondaryOBDECU_XIX_SoC_XIX_BMC_HV.RP_IF_DCDC_NV_Komponentenfehler_49_XIX_HVB_Fehlerausgabe_SecondaryOBDECU_XIX_SoC_XIX_BMC_HV <-> outer port RP_IF_DCDC_NV_Komponentenfehler_49_XIX_BMC_HV  # _XIX_DCDC_SystemControl_XIX_HV_Laden_XIX_DCDC_HV_XIX_HVB_Fehlerausgabe_SecondaryOBDECU_XIX_SoC_XIX_BMC_HV_XIX_DCDC_NV_Komponentenfehler_49
    delegate HVB_Fehlerausgabe_SecondaryOBDECU_XIX_SoC_XIX_BMC_HV.RP_IF_DCDC_NV_Komponentenfehler_12_XIX_HVB_Fehlerausgabe_SecondaryOBDECU_XIX_SoC_XIX_BMC_HV <-> outer port RP_IF_DCDC_NV_Komponentenfehler_12_XIX_BMC_HV  # _XIX_DCDC_SystemControl_XIX_HV_Laden_XIX_DCDC_HV_XIX_HVB_Fehlerausgabe_SecondaryOBDECU_XIX_SoC_XIX_BMC_HV_XIX_DCDC_NV_Komponentenfehler_12
    delegate HVB_Fehlerausgabe_SecondaryOBDECU_XIX_SoC_XIX_BMC_HV.RP_IF_DCDC_NV_Komponentenfehler_42_XIX_HVB_Fehlerausgabe_SecondaryOBDECU_XIX_SoC_XIX_BMC_HV <-> outer port RP_IF_DCDC_NV_Komponentenfehler_42_XIX_BMC_HV  # _XIX_DCDC_SystemControl_XIX_HV_Laden_XIX_DCDC_HV_XIX_HVB_Fehlerausgabe_SecondaryOBDECU_XIX_SoC_XIX_BMC_HV_XIX_DCDC_NV_Komponentenfehler_42
    delegate HVB_Fehlerausgabe_SecondaryOBDECU_XIX_SoC_XIX_BMC_HV.RP_IF_DCDC_NV_Komponentenfehler_3_4_XIX_HVB_Fehlerausgabe_SecondaryOBDECU_XIX_SoC_XIX_BMC_HV <-> outer port RP_IF_DCDC_NV_Komponentenfehler_3_4_XIX_BMC_HV  # _XIX_DCDC_SystemControl_XIX_HV_Laden_XIX_DCDC_HV_XIX_HVB_Fehlerausgabe_SecondaryOBDECU_XIX_SoC_XIX_BMC_HV_XIX_DCDC_NV_Komponentenfehler_3_4
    delegate HVB_Fehlerausgabe_SecondaryOBDECU_XIX_SoC_XIX_BMC_HV.RP_IF_DCDC_NV_Komponentenfehler_71_XIX_HVB_Fehlerausgabe_SecondaryOBDECU_XIX_SoC_XIX_BMC_HV <-> outer port RP_IF_DCDC_NV_Komponentenfehler_71_XIX_BMC_HV  # _XIX_DCDC_SystemControl_XIX_HV_Laden_XIX_DCDC_HV_XIX_HVB_Fehlerausgabe_SecondaryOBDECU_XIX_SoC_XIX_BMC_HV_XIX_DCDC_NV_Komponentenfehler_71
    delegate HVB_Fehlerausgabe_SecondaryOBDECU_XIX_SoC_XIX_BMC_HV.RP_IF_DCDC_NV_Komponentenfehler_29_XIX_HVB_Fehlerausgabe_SecondaryOBDECU_XIX_SoC_XIX_BMC_HV <-> outer port RP_IF_DCDC_NV_Komponentenfehler_29_XIX_BMC_HV  # _XIX_DCDC_SystemControl_XIX_HV_Laden_XIX_DCDC_HV_XIX_HVB_Fehlerausgabe_SecondaryOBDECU_XIX_SoC_XIX_BMC_HV_XIX_DCDC_NV_Komponentenfehler_29
    delegate HVB_Fehlerausgabe_SecondaryOBDECU_XIX_SoC_XIX_BMC_HV.RP_IF_DCDC_NV_Komponentenfehler_21_XIX_HVB_Fehlerausgabe_SecondaryOBDECU_XIX_SoC_XIX_BMC_HV <-> outer port RP_IF_DCDC_NV_Komponentenfehler_21_XIX_BMC_HV  # _XIX_DCDC_SystemControl_XIX_HV_Laden_XIX_DCDC_HV_XIX_HVB_Fehlerausgabe_SecondaryOBDECU_XIX_SoC_XIX_BMC_HV_XIX_DCDC_NV_Komponentenfehler_21
    delegate HVB_Fehlerausgabe_SecondaryOBDECU_XIX_SoC_XIX_BMC_HV.RP_IF_DCDC_NV_Komponentenfehler_78_XIX_HVB_Fehlerausgabe_SecondaryOBDECU_XIX_SoC_XIX_BMC_HV <-> outer port RP_IF_DCDC_NV_Komponentenfehler_78_XIX_BMC_HV  # _XIX_DCDC_SystemControl_XIX_HV_Laden_XIX_DCDC_HV_XIX_HVB_Fehlerausgabe_SecondaryOBDECU_XIX_SoC_XIX_BMC_HV_XIX_DCDC_NV_Komponentenfehler_78
    delegate HVB_Fehlerausgabe_SecondaryOBDECU_XIX_SoC_XIX_BMC_HV.RP_IF_DCDC_NV_Komponentenfehler_23_XIX_HVB_Fehlerausgabe_SecondaryOBDECU_XIX_SoC_XIX_BMC_HV <-> outer port RP_IF_DCDC_NV_Komponentenfehler_23_XIX_BMC_HV  # _XIX_DCDC_SystemControl_XIX_HV_Laden_XIX_DCDC_HV_XIX_HVB_Fehlerausgabe_SecondaryOBDECU_XIX_SoC_XIX_BMC_HV_XIX_DCDC_NV_Komponentenfehler_23
    delegate HVB_Fehlerausgabe_SecondaryOBDECU_XIX_SoC_XIX_BMC_HV.RP_IF_DCDC_NV_Komponentenfehler_80_XIX_HVB_Fehlerausgabe_SecondaryOBDECU_XIX_SoC_XIX_BMC_HV <-> outer port RP_IF_DCDC_NV_Komponentenfehler_80_XIX_BMC_HV  # _XIX_DCDC_SystemControl_XIX_HV_Laden_XIX_DCDC_HV_XIX_HVB_Fehlerausgabe_SecondaryOBDECU_XIX_SoC_XIX_BMC_HV_XIX_DCDC_NV_Komponentenfehler_80
    delegate HVB_Fehlerausgabe_SecondaryOBDECU_XIX_SoC_XIX_BMC_HV.RP_IF_DCDC_NV_Komponentenfehler_75_XIX_HVB_Fehlerausgabe_SecondaryOBDECU_XIX_SoC_XIX_BMC_HV <-> outer port RP_IF_DCDC_NV_Komponentenfehler_75_XIX_BMC_HV  # _XIX_DCDC_SystemControl_XIX_HV_Laden_XIX_DCDC_HV_XIX_HVB_Fehlerausgabe_SecondaryOBDECU_XIX_SoC_XIX_BMC_HV_XIX_DCDC_NV_Komponentenfehler_75
    delegate HVB_Fehlerausgabe_SecondaryOBDECU_XIX_SoC_XIX_BMC_HV.RP_IF_DCDC_NV_Komponentenfehler_57_XIX_HVB_Fehlerausgabe_SecondaryOBDECU_XIX_SoC_XIX_BMC_HV <-> outer port RP_IF_DCDC_NV_Komponentenfehler_57_XIX_BMC_HV  # _XIX_DCDC_SystemControl_XIX_HV_Laden_XIX_DCDC_HV_XIX_HVB_Fehlerausgabe_SecondaryOBDECU_XIX_SoC_XIX_BMC_HV_XIX_DCDC_NV_Komponentenfehler_57
    delegate HVB_Fehlerausgabe_SecondaryOBDECU_XIX_SoC_XIX_BMC_HV.RP_IF_DCDC_NV_Komponentenfehler_39_XIX_HVB_Fehlerausgabe_SecondaryOBDECU_XIX_SoC_XIX_BMC_HV <-> outer port RP_IF_DCDC_NV_Komponentenfehler_39_XIX_BMC_HV  # _XIX_DCDC_SystemControl_XIX_HV_Laden_XIX_DCDC_HV_XIX_HVB_Fehlerausgabe_SecondaryOBDECU_XIX_SoC_XIX_BMC_HV_XIX_DCDC_NV_Komponentenfehler_39
    delegate HVB_Fehlerausgabe_SecondaryOBDECU_XIX_SoC_XIX_BMC_HV.RP_IF_DCDC_NV_Komponentenfehler_63_XIX_HVB_Fehlerausgabe_SecondaryOBDECU_XIX_SoC_XIX_BMC_HV <-> outer port RP_IF_DCDC_NV_Komponentenfehler_63_XIX_BMC_HV  # _XIX_DCDC_SystemControl_XIX_HV_Laden_XIX_DCDC_HV_XIX_HVB_Fehlerausgabe_SecondaryOBDECU_XIX_SoC_XIX_BMC_HV_XIX_DCDC_NV_Komponentenfehler_63
    delegate HVB_Fehlerausgabe_SecondaryOBDECU_XIX_SoC_XIX_BMC_HV.RP_IF_DCDC_NV_Komponentenfehler_28_XIX_HVB_Fehlerausgabe_SecondaryOBDECU_XIX_SoC_XIX_BMC_HV <-> outer port RP_IF_DCDC_NV_Komponentenfehler_28_XIX_BMC_HV  # _XIX_DCDC_SystemControl_XIX_HV_Laden_XIX_DCDC_HV_XIX_HVB_Fehlerausgabe_SecondaryOBDECU_XIX_SoC_XIX_BMC_HV_XIX_DCDC_NV_Komponentenfehler_28
    delegate HVB_Fehlerausgabe_SecondaryOBDECU_XIX_SoC_XIX_BMC_HV.RP_IF_DCDC_NV_Komponentenfehler_19_XIX_HVB_Fehlerausgabe_SecondaryOBDECU_XIX_SoC_XIX_BMC_HV <-> outer port RP_IF_DCDC_NV_Komponentenfehler_19_XIX_BMC_HV  # _XIX_DCDC_SystemControl_XIX_HV_Laden_XIX_DCDC_HV_XIX_HVB_Fehlerausgabe_SecondaryOBDECU_XIX_SoC_XIX_BMC_HV_XIX_DCDC_NV_Komponentenfehler_19
    delegate HVB_Fehlerausgabe_SecondaryOBDECU_XIX_SoC_XIX_BMC_HV.RP_IF_DCDC_NV_Komponentenfehler_60_XIX_HVB_Fehlerausgabe_SecondaryOBDECU_XIX_SoC_XIX_BMC_HV <-> outer port RP_IF_DCDC_NV_Komponentenfehler_60_XIX_BMC_HV  # _XIX_DCDC_SystemControl_XIX_HV_Laden_XIX_DCDC_HV_XIX_HVB_Fehlerausgabe_SecondaryOBDECU_XIX_SoC_XIX_BMC_HV_XIX_DCDC_NV_Komponentenfehler_60
    delegate HVB_Fehlerausgabe_SecondaryOBDECU_XIX_SoC_XIX_BMC_HV.RP_IF_DCDC_NV_Komponentenfehler_3_11_XIX_HVB_Fehlerausgabe_SecondaryOBDECU_XIX_SoC_XIX_BMC_HV <-> outer port RP_IF_DCDC_NV_Komponentenfehler_3_11_XIX_BMC_HV  # _XIX_DCDC_SystemControl_XIX_HV_Laden_XIX_DCDC_HV_XIX_HVB_Fehlerausgabe_SecondaryOBDECU_XIX_SoC_XIX_BMC_HV_XIX_DCDC_NV_Komponentenfehler_3_11
    delegate HVB_Fehlerausgabe_SecondaryOBDECU_XIX_SoC_XIX_BMC_HV.RP_IF_DCDC_NV_Komponentenfehler_41_XIX_HVB_Fehlerausgabe_SecondaryOBDECU_XIX_SoC_XIX_BMC_HV <-> outer port RP_IF_DCDC_NV_Komponentenfehler_41_XIX_BMC_HV  # _XIX_DCDC_SystemControl_XIX_HV_Laden_XIX_DCDC_HV_XIX_HVB_Fehlerausgabe_SecondaryOBDECU_XIX_SoC_XIX_BMC_HV_XIX_DCDC_NV_Komponentenfehler_41
    delegate HVB_Fehlerausgabe_SecondaryOBDECU_XIX_SoC_XIX_BMC_HV.RP_IF_DCDC_NV_Komponentenfehler_37_XIX_HVB_Fehlerausgabe_SecondaryOBDECU_XIX_SoC_XIX_BMC_HV <-> outer port RP_IF_DCDC_NV_Komponentenfehler_37_XIX_BMC_HV  # _XIX_DCDC_SystemControl_XIX_HV_Laden_XIX_DCDC_HV_XIX_HVB_Fehlerausgabe_SecondaryOBDECU_XIX_SoC_XIX_BMC_HV_XIX_DCDC_NV_Komponentenfehler_37
    delegate HVB_Fehlerausgabe_SecondaryOBDECU_XIX_SoC_XIX_BMC_HV.RP_IF_DCDC_NV_Komponentenfehler_3_9_XIX_HVB_Fehlerausgabe_SecondaryOBDECU_XIX_SoC_XIX_BMC_HV <-> outer port RP_IF_DCDC_NV_Komponentenfehler_3_9_XIX_BMC_HV  # _XIX_DCDC_SystemControl_XIX_HV_Laden_XIX_DCDC_HV_XIX_HVB_Fehlerausgabe_SecondaryOBDECU_XIX_SoC_XIX_BMC_HV_XIX_DCDC_NV_Komponentenfehler_3_9
    delegate HVB_Fehlerausgabe_SecondaryOBDECU_XIX_SoC_XIX_BMC_HV.RP_IF_DCDC_NV_Komponentenfehler_01_XIX_HVB_Fehlerausgabe_SecondaryOBDECU_XIX_SoC_XIX_BMC_HV <-> outer port RP_IF_DCDC_NV_Komponentenfehler_01_XIX_BMC_HV  # _XIX_DCDC_SystemControl_XIX_HV_Laden_XIX_DCDC_HV_XIX_HVB_Fehlerausgabe_SecondaryOBDECU_XIX_SoC_XIX_BMC_HV_XIX_DCDC_NV_Komponentenfehler_01
    delegate HVB_Fehlerausgabe_SecondaryOBDECU_XIX_SoC_XIX_BMC_HV.RP_IF_DCDC_NV_Komponentenfehler_61_XIX_HVB_Fehlerausgabe_SecondaryOBDECU_XIX_SoC_XIX_BMC_HV <-> outer port RP_IF_DCDC_NV_Komponentenfehler_61_XIX_BMC_HV  # _XIX_DCDC_SystemControl_XIX_HV_Laden_XIX_DCDC_HV_XIX_HVB_Fehlerausgabe_SecondaryOBDECU_XIX_SoC_XIX_BMC_HV_XIX_DCDC_NV_Komponentenfehler_61
    delegate HVB_Fehlerausgabe_SecondaryOBDECU_XIX_SoC_XIX_BMC_HV.RP_IF_DCDC_NV_Komponentenfehler_64_XIX_HVB_Fehlerausgabe_SecondaryOBDECU_XIX_SoC_XIX_BMC_HV <-> outer port RP_IF_DCDC_NV_Komponentenfehler_64_XIX_BMC_HV  # _XIX_DCDC_SystemControl_XIX_HV_Laden_XIX_DCDC_HV_XIX_HVB_Fehlerausgabe_SecondaryOBDECU_XIX_SoC_XIX_BMC_HV_XIX_DCDC_NV_Komponentenfehler_64
    delegate HVB_Fehlerausgabe_SecondaryOBDECU_XIX_SoC_XIX_BMC_HV.RP_IF_DCDC_NV_Komponentenfehler_62_XIX_HVB_Fehlerausgabe_SecondaryOBDECU_XIX_SoC_XIX_BMC_HV <-> outer port RP_IF_DCDC_NV_Komponentenfehler_62_XIX_BMC_HV  # _XIX_DCDC_SystemControl_XIX_HV_Laden_XIX_DCDC_HV_XIX_HVB_Fehlerausgabe_SecondaryOBDECU_XIX_SoC_XIX_BMC_HV_XIX_DCDC_NV_Komponentenfehler_62
    delegate HVB_Fehlerausgabe_SecondaryOBDECU_XIX_SoC_XIX_BMC_HV.RP_IF_DCDC_NV_Komponentenfehler_10_XIX_HVB_Fehlerausgabe_SecondaryOBDECU_XIX_SoC_XIX_BMC_HV <-> outer port RP_IF_DCDC_NV_Komponentenfehler_10_XIX_BMC_HV  # _XIX_DCDC_SystemControl_XIX_HV_Laden_XIX_DCDC_HV_XIX_HVB_Fehlerausgabe_SecondaryOBDECU_XIX_SoC_XIX_BMC_HV_XIX_DCDC_NV_Komponentenfehler_10
    delegate HVB_Fehlerausgabe_SecondaryOBDECU_XIX_SoC_XIX_BMC_HV.RP_IF_DCDC_NV_Komponentenfehler_24_XIX_HVB_Fehlerausgabe_SecondaryOBDECU_XIX_SoC_XIX_BMC_HV <-> outer port RP_IF_DCDC_NV_Komponentenfehler_24_XIX_BMC_HV  # _XIX_DCDC_SystemControl_XIX_HV_Laden_XIX_DCDC_HV_XIX_HVB_Fehlerausgabe_SecondaryOBDECU_XIX_SoC_XIX_BMC_HV_XIX_DCDC_NV_Komponentenfehler_24
    delegate diagnosis_infrastructure_Hybrid_01_XIX_diagnosis_infrastructure_XIX_BMC_HV.RP_IF_DW_Kilometerstand_XIX_diagnosis_infrastructure_Hybrid_01_XIX_diagnosis_infrastructure_XIX_BMC_HV <-> outer port RP_IF_DW_Kilometerstand_XIX_BMC_HV  # _XIX_DiagnoseWegstrecke_XIX_DiagBasis_XIX_HCP5_P1_Gateway_XIX_diagnosis_infrastructure_Hybrid_01_XIX_diagnosis_infrastructure_XIX_BMC_HV_XIX_DW_Kilometerstand
    delegate HochvoltBatterieManagement_XIX_SoC_XIX_BMC_HV.RP_IF_SG_HVLM_14_XIX_HochvoltBatterieManagement_XIX_SoC_XIX_BMC_HV <-> outer port RP_IF_SG_HVLM_14_XIX_BMC_HV
    delegate HochvoltBatterieManagement_XIX_SoC_XIX_BMC_HV.RP_IF_HVLM_BCAM_Aktiv_XIX_HochvoltBatterieManagement_XIX_SoC_XIX_BMC_HV <-> outer port RP_IF_HVLM_BCAM_Aktiv_XIX_BMC_HV
    delegate HochvoltBatterieManagement_XIX_SoC_XIX_BMC_HV.RP_IF_HVLM_BidiLadeModus_XIX_HochvoltBatterieManagement_XIX_SoC_XIX_BMC_HV <-> outer port RP_IF_HVLM_BidiLadeModus_XIX_BMC_HV
    delegate HV_Batterie_RTM_XIX_RTM_XIX_BMC_HV.SP_IF_BMC_CMC_Temperatur_{001..019}_XIX_HV_Batterie_RTM_XIX_RTM_XIX_BMC_HV <-> outer port SP_IF_BMC_CMC_Temperatur_{001..019}_XIX_BMC_HV
    delegate HV_Batterie_RTM_XIX_RTM_XIX_BMC_HV.SP_IF_BMC_CMC_Temperatur_01_Messzeit_XIX_HV_Batterie_RTM_XIX_RTM_XIX_BMC_HV <-> outer port SP_IF_BMC_CMC_Temperatur_01_Messzeit_XIX_BMC_HV
    delegate HV_Batterie_RTM_XIX_RTM_XIX_BMC_HV.SP_IF_BMC_CMC_Temperatur_{020..029}_XIX_HV_Batterie_RTM_XIX_RTM_XIX_BMC_HV <-> outer port SP_IF_BMC_CMC_Temperatur_{020..029}_XIX_BMC_HV
    delegate HV_Batterie_RTM_XIX_RTM_XIX_BMC_HV.SP_IF_BMC_CMC_Temperatur_02_Messzeit_XIX_HV_Batterie_RTM_XIX_RTM_XIX_BMC_HV <-> outer port SP_IF_BMC_CMC_Temperatur_02_Messzeit_XIX_BMC_HV
    delegate HV_Batterie_RTM_XIX_RTM_XIX_BMC_HV.SP_IF_BMC_CMC_Temperatur_{030..039}_XIX_HV_Batterie_RTM_XIX_RTM_XIX_BMC_HV <-> outer port SP_IF_BMC_CMC_Temperatur_{030..039}_XIX_BMC_HV
    delegate HV_Batterie_RTM_XIX_RTM_XIX_BMC_HV.SP_IF_BMC_CMC_Temperatur_03_Messzeit_XIX_HV_Batterie_RTM_XIX_RTM_XIX_BMC_HV <-> outer port SP_IF_BMC_CMC_Temperatur_03_Messzeit_XIX_BMC_HV
    delegate HV_Batterie_RTM_XIX_RTM_XIX_BMC_HV.SP_IF_BMC_CMC_Temperatur_{040..096}_XIX_HV_Batterie_RTM_XIX_RTM_XIX_BMC_HV <-> outer port SP_IF_BMC_CMC_Temperatur_{040..096}_XIX_BMC_HV
    delegate HV_Batterie_RTM_XIX_RTM_XIX_BMC_HV.SP_IF_BMC_CMC_Zellspannung_{001..019}_XIX_HV_Batterie_RTM_XIX_RTM_XIX_BMC_HV <-> outer port SP_IF_BMC_CMC_Zellspannung_{001..019}_XIX_BMC_HV
    delegate HV_Batterie_RTM_XIX_RTM_XIX_BMC_HV.SP_IF_BMC_CMC_Zellspannung_01_Messzeit_XIX_HV_Batterie_RTM_XIX_RTM_XIX_BMC_HV <-> outer port SP_IF_BMC_CMC_Zellspannung_01_Messzeit_XIX_BMC_HV
    delegate HV_Batterie_RTM_XIX_RTM_XIX_BMC_HV.SP_IF_BMC_CMC_Zellspannung_{020..029}_XIX_HV_Batterie_RTM_XIX_RTM_XIX_BMC_HV <-> outer port SP_IF_BMC_CMC_Zellspannung_{020..029}_XIX_BMC_HV
    delegate HV_Batterie_RTM_XIX_RTM_XIX_BMC_HV.SP_IF_BMC_CMC_Zellspannung_02_Messzeit_XIX_HV_Batterie_RTM_XIX_RTM_XIX_BMC_HV <-> outer port SP_IF_BMC_CMC_Zellspannung_02_Messzeit_XIX_BMC_HV
    delegate HV_Batterie_RTM_XIX_RTM_XIX_BMC_HV.SP_IF_BMC_CMC_Zellspannung_{030..039}_XIX_HV_Batterie_RTM_XIX_RTM_XIX_BMC_HV <-> outer port SP_IF_BMC_CMC_Zellspannung_{030..039}_XIX_BMC_HV
    delegate HV_Batterie_RTM_XIX_RTM_XIX_BMC_HV.SP_IF_BMC_CMC_Zellspannung_03_Messzeit_XIX_HV_Batterie_RTM_XIX_RTM_XIX_BMC_HV <-> outer port SP_IF_BMC_CMC_Zellspannung_03_Messzeit_XIX_BMC_HV
    delegate HV_Batterie_RTM_XIX_RTM_XIX_BMC_HV.SP_IF_BMC_CMC_Zellspannung_{040..049}_XIX_HV_Batterie_RTM_XIX_RTM_XIX_BMC_HV <-> outer port SP_IF_BMC_CMC_Zellspannung_{040..049}_XIX_BMC_HV
    delegate HV_Batterie_RTM_XIX_RTM_XIX_BMC_HV.SP_IF_BMC_CMC_Zellspannung_04_Messzeit_XIX_HV_Batterie_RTM_XIX_RTM_XIX_BMC_HV <-> outer port SP_IF_BMC_CMC_Zellspannung_04_Messzeit_XIX_BMC_HV
    delegate HV_Batterie_RTM_XIX_RTM_XIX_BMC_HV.SP_IF_BMC_CMC_Zellspannung_{050..059}_XIX_HV_Batterie_RTM_XIX_RTM_XIX_BMC_HV <-> outer port SP_IF_BMC_CMC_Zellspannung_{050..059}_XIX_BMC_HV
    delegate HV_Batterie_RTM_XIX_RTM_XIX_BMC_HV.SP_IF_BMC_CMC_Zellspannung_05_Messzeit_XIX_HV_Batterie_RTM_XIX_RTM_XIX_BMC_HV <-> outer port SP_IF_BMC_CMC_Zellspannung_05_Messzeit_XIX_BMC_HV
    delegate HV_Batterie_RTM_XIX_RTM_XIX_BMC_HV.SP_IF_BMC_CMC_Zellspannung_{060..192}_XIX_HV_Batterie_RTM_XIX_RTM_XIX_BMC_HV <-> outer port SP_IF_BMC_CMC_Zellspannung_{060..192}_XIX_BMC_HV
    delegate HV_Batterie_RTM_XIX_RTM_XIX_BMC_HV.SP_IF_BMC_IstTemperaturMax_Modul_ID_XIX_HV_Batterie_RTM_XIX_RTM_XIX_BMC_HV <-> outer port SP_IF_BMC_IstTemperaturMax_Modul_ID_XIX_BMC_HV
    delegate HV_Batterie_RTM_XIX_RTM_XIX_BMC_HV.SP_IF_BMC_IstTemperaturMax_Sensor_ID_XIX_HV_Batterie_RTM_XIX_RTM_XIX_BMC_HV <-> outer port SP_IF_BMC_IstTemperaturMax_Sensor_ID_XIX_BMC_HV
    delegate HV_Batterie_RTM_XIX_RTM_XIX_BMC_HV.SP_IF_BMC_IstTemperaturMin_Modul_ID_XIX_HV_Batterie_RTM_XIX_RTM_XIX_BMC_HV <-> outer port SP_IF_BMC_IstTemperaturMin_Modul_ID_XIX_BMC_HV
    delegate HV_Batterie_RTM_XIX_RTM_XIX_BMC_HV.SP_IF_BMC_IstTemperaturMin_Sensor_ID_XIX_HV_Batterie_RTM_XIX_RTM_XIX_BMC_HV <-> outer port SP_IF_BMC_IstTemperaturMin_Sensor_ID_XIX_BMC_HV
    delegate HV_Batterie_RTM_XIX_RTM_XIX_BMC_HV.SP_IF_BMC_IstZellSpannungMax_Modul_ID_XIX_HV_Batterie_RTM_XIX_RTM_XIX_BMC_HV <-> outer port SP_IF_BMC_IstZellSpannungMax_Modul_ID_XIX_BMC_HV
    delegate HV_Batterie_RTM_XIX_RTM_XIX_BMC_HV.SP_IF_BMC_IstZellSpannungMax_Zell_ID_XIX_HV_Batterie_RTM_XIX_RTM_XIX_BMC_HV <-> outer port SP_IF_BMC_IstZellSpannungMax_Zell_ID_XIX_BMC_HV
    delegate HV_Batterie_RTM_XIX_RTM_XIX_BMC_HV.SP_IF_BMC_IstZellSpannungMin_Modul_ID_XIX_HV_Batterie_RTM_XIX_RTM_XIX_BMC_HV <-> outer port SP_IF_BMC_IstZellSpannungMin_Modul_ID_XIX_BMC_HV
